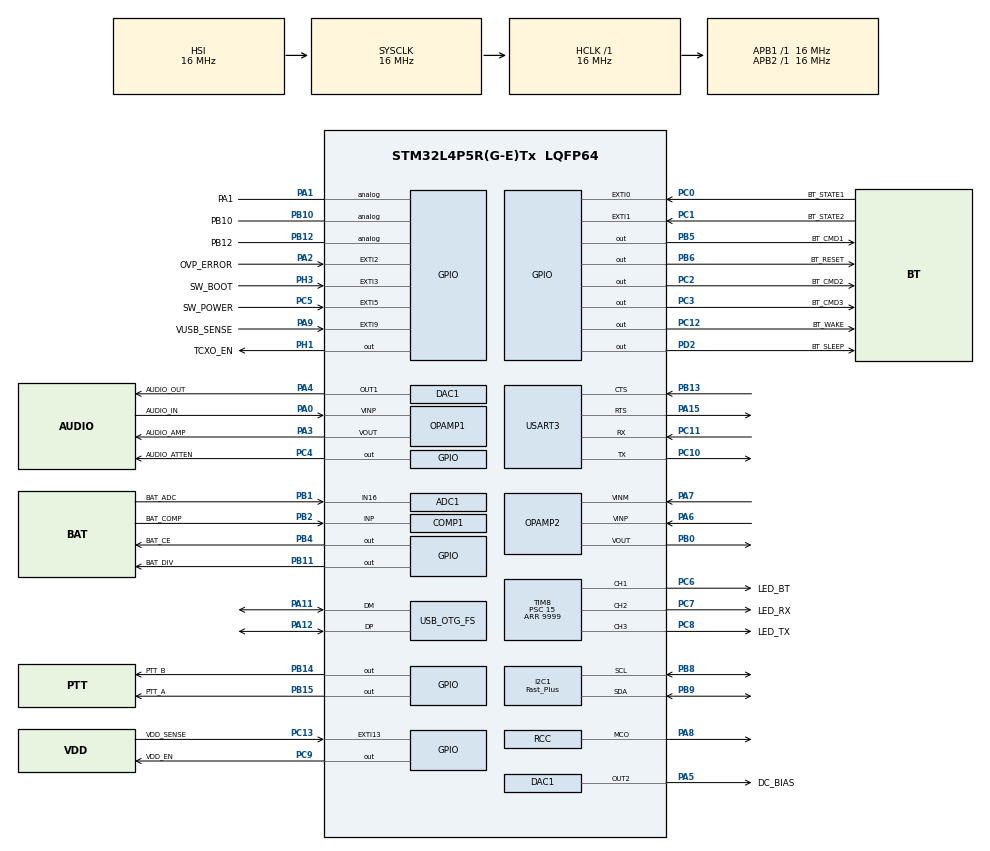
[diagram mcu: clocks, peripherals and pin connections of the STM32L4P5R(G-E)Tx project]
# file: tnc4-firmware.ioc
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ADC1.Channel-0\#ChannelRegularConversion=ADC_CHANNEL_16
ADC1.DMAContinuousRequests=DISABLE
ADC1.ExternalTrigConv=ADC_SOFTWARE_START
ADC1.NbrOfConversionFlag=1
ADC1.OffsetNumber-0\#ChannelRegularConversion=ADC_OFFSET_NONE
ADC1.OversamplingMode=ENABLE
ADC1.Rank-0\#ChannelRegularConversion=1
ADC1.Ratio=ADC_OVERSAMPLING_RATIO_16
ADC1.RightBitShift=ADC_RIGHTBITSHIFT_2
ADC1.SamplingTime-0\#ChannelRegularConversion=ADC_SAMPLETIME_640CYCLES_5
ADC1.master=1
ADC2.Channel-4\#ChannelRegularConversion=ADC_CHANNEL_8
ADC2.ClockPrescaler=ADC_CLOCK_ASYNC_DIV1
ADC2.DMAContinuousRequests=ENABLE
ADC2.ExternalTrigConv=ADC_EXTERNALTRIG_T6_TRGO
ADC2.NbrOfConversionFlag=1
ADC2.OffsetNumber-4\#ChannelRegularConversion=ADC_OFFSET_NONE
ADC2.OversamplingMode=ENABLE
ADC2.Rank-4\#ChannelRegularConversion=1
ADC2.Ratio=ADC_OVERSAMPLING_RATIO_16
ADC2.RightBitShift=ADC_RIGHTBITSHIFT_2
ADC2.SamplingTime-4\#ChannelRegularConversion=ADC_SAMPLETIME_24CYCLES_5
COMP1.Hysteresis=COMP_HYSTERESIS_LOW
COMP1.Mode=COMP_POWERMODE_ULTRALOWPOWER
COMP1.TriggerMode=COMP_TRIGGERMODE_IT_FALLING
CRC.CRCLength=CRC_POLYLENGTH_16B
CRC.DefaultInitValueUse=DEFAULT_INIT_VALUE_DISABLE
CRC.DefaultPolynomialUse=DEFAULT_POLYNOMIAL_DISABLE
CRC.GeneratingPolynomial=X12+X5+X0
CRC.InitValue=0xFFFF
CRC.InputDataInversionMode=CRC_INPUTDATA_INVERSION_BYTE
DAC1.DAC_Channel-DAC_OUT2=DAC_CHANNEL_2
DAC1.DAC_SampleAndHold-DAC_OUT2=DAC_SAMPLEANDHOLD_DISABLE
DAC1.DAC_Trigger-DAC_OUT1=DAC_TRIGGER_T7_TRGO
Dma.ADC2.5.Direction=DMA_PERIPH_TO_MEMORY
Dma.ADC2.5.EventEnable=ENABLE
Dma.ADC2.5.Instance=DMA1_Channel3
Dma.ADC2.5.MemDataAlignment=DMA_MDATAALIGN_HALFWORD
Dma.ADC2.5.MemInc=DMA_MINC_ENABLE
Dma.ADC2.5.Mode=DMA_CIRCULAR
Dma.ADC2.5.PeriphDataAlignment=DMA_PDATAALIGN_HALFWORD
Dma.ADC2.5.PeriphInc=DMA_PINC_DISABLE
Dma.ADC2.5.Polarity=HAL_DMAMUX_REQ_GEN_RISING
Dma.ADC2.5.Priority=DMA_PRIORITY_LOW
Dma.ADC2.5.RequestNumber=1
Dma.ADC2.5.SignalID=NONE
Dma.ADC2.5.SyncEnable=DISABLE
Dma.ADC2.5.SyncPolarity=HAL_DMAMUX_SYNC_NO_EVENT
Dma.ADC2.5.SyncRequestNumber=1
Dma.ADC2.5.SyncSignalID=NONE
Dma.DAC1_CH1.2.Direction=DMA_MEMORY_TO_PERIPH
Dma.DAC1_CH1.2.EventEnable=DISABLE
Dma.DAC1_CH1.2.Instance=DMA1_Channel4
Dma.DAC1_CH1.2.MemDataAlignment=DMA_MDATAALIGN_HALFWORD
Dma.DAC1_CH1.2.MemInc=DMA_MINC_ENABLE
Dma.DAC1_CH1.2.Mode=DMA_CIRCULAR
Dma.DAC1_CH1.2.PeriphDataAlignment=DMA_PDATAALIGN_HALFWORD
Dma.DAC1_CH1.2.PeriphInc=DMA_PINC_DISABLE
Dma.DAC1_CH1.2.Polarity=HAL_DMAMUX_REQ_GEN_RISING
Dma.DAC1_CH1.2.Priority=DMA_PRIORITY_VERY_HIGH
Dma.DAC1_CH1.2.RequestNumber=1
Dma.DAC1_CH1.2.SignalID=NONE
Dma.DAC1_CH1.2.SyncEnable=DISABLE
Dma.DAC1_CH1.2.SyncPolarity=HAL_DMAMUX_SYNC_NO_EVENT
Dma.DAC1_CH1.2.SyncRequestNumber=1
Dma.DAC1_CH1.2.SyncSignalID=NONE
Dma.I2C1_RX.3.Direction=DMA_PERIPH_TO_MEMORY
Dma.I2C1_RX.3.EventEnable=DISABLE
Dma.I2C1_RX.3.Instance=DMA1_Channel5
Dma.I2C1_RX.3.MemDataAlignment=DMA_MDATAALIGN_BYTE
Dma.I2C1_RX.3.MemInc=DMA_MINC_ENABLE
Dma.I2C1_RX.3.Mode=DMA_NORMAL
Dma.I2C1_RX.3.PeriphDataAlignment=DMA_PDATAALIGN_BYTE
Dma.I2C1_RX.3.PeriphInc=DMA_PINC_DISABLE
Dma.I2C1_RX.3.Polarity=HAL_DMAMUX_REQ_GEN_RISING
Dma.I2C1_RX.3.Priority=DMA_PRIORITY_LOW
Dma.I2C1_RX.3.RequestNumber=1
Dma.I2C1_RX.3.SignalID=NONE
Dma.I2C1_RX.3.SyncEnable=DISABLE
Dma.I2C1_RX.3.SyncPolarity=HAL_DMAMUX_SYNC_NO_EVENT
Dma.I2C1_RX.3.SyncRequestNumber=1
Dma.I2C1_RX.3.SyncSignalID=NONE
Dma.I2C1_TX.4.Direction=DMA_MEMORY_TO_PERIPH
Dma.I2C1_TX.4.EventEnable=DISABLE
Dma.I2C1_TX.4.Instance=DMA1_Channel6
Dma.I2C1_TX.4.MemDataAlignment=DMA_MDATAALIGN_BYTE
Dma.I2C1_TX.4.MemInc=DMA_MINC_ENABLE
Dma.I2C1_TX.4.Mode=DMA_NORMAL
Dma.I2C1_TX.4.PeriphDataAlignment=DMA_PDATAALIGN_BYTE
Dma.I2C1_TX.4.PeriphInc=DMA_PINC_DISABLE
Dma.I2C1_TX.4.Polarity=HAL_DMAMUX_REQ_GEN_RISING
Dma.I2C1_TX.4.Priority=DMA_PRIORITY_LOW
Dma.I2C1_TX.4.RequestNumber=1
Dma.I2C1_TX.4.SignalID=NONE
Dma.I2C1_TX.4.SyncEnable=DISABLE
Dma.I2C1_TX.4.SyncPolarity=HAL_DMAMUX_SYNC_NO_EVENT
Dma.I2C1_TX.4.SyncRequestNumber=1
Dma.I2C1_TX.4.SyncSignalID=NONE
Dma.Request0=USART3_RX
Dma.Request1=USART3_TX
Dma.Request2=DAC1_CH1
Dma.Request3=I2C1_RX
Dma.Request4=I2C1_TX
Dma.Request5=ADC2
Dma.USART3_RX.0.Direction=DMA_PERIPH_TO_MEMORY
Dma.USART3_RX.0.EventEnable=DISABLE
Dma.USART3_RX.0.Instance=DMA1_Channel1
Dma.USART3_RX.0.MemDataAlignment=DMA_MDATAALIGN_BYTE
Dma.USART3_RX.0.MemInc=DMA_MINC_ENABLE
Dma.USART3_RX.0.Mode=DMA_CIRCULAR
Dma.USART3_RX.0.PeriphDataAlignment=DMA_PDATAALIGN_BYTE
Dma.USART3_RX.0.PeriphInc=DMA_PINC_DISABLE
Dma.USART3_RX.0.Polarity=HAL_DMAMUX_REQ_GEN_RISING
Dma.USART3_RX.0.Priority=DMA_PRIORITY_MEDIUM
Dma.USART3_RX.0.RequestNumber=1
Dma.USART3_RX.0.SignalID=NONE
Dma.USART3_RX.0.SyncEnable=DISABLE
Dma.USART3_RX.0.SyncPolarity=HAL_DMAMUX_SYNC_NO_EVENT
Dma.USART3_RX.0.SyncRequestNumber=1
Dma.USART3_RX.0.SyncSignalID=NONE
Dma.USART3_TX.1.Direction=DMA_MEMORY_TO_PERIPH
Dma.USART3_TX.1.EventEnable=DISABLE
Dma.USART3_TX.1.Instance=DMA1_Channel2
Dma.USART3_TX.1.MemDataAlignment=DMA_MDATAALIGN_BYTE
Dma.USART3_TX.1.MemInc=DMA_MINC_ENABLE
Dma.USART3_TX.1.Mode=DMA_NORMAL
Dma.USART3_TX.1.PeriphDataAlignment=DMA_PDATAALIGN_BYTE
Dma.USART3_TX.1.PeriphInc=DMA_PINC_DISABLE
Dma.USART3_TX.1.Polarity=HAL_DMAMUX_REQ_GEN_RISING
Dma.USART3_TX.1.Priority=DMA_PRIORITY_MEDIUM
Dma.USART3_TX.1.RequestNumber=1
Dma.USART3_TX.1.SignalID=NONE
Dma.USART3_TX.1.SyncEnable=DISABLE
Dma.USART3_TX.1.SyncPolarity=HAL_DMAMUX_SYNC_NO_EVENT
Dma.USART3_TX.1.SyncRequestNumber=1
Dma.USART3_TX.1.SyncSignalID=NONE
FREERTOS.HEAP_NUMBER=3
FREERTOS.Queues01=ioEventQueue,16,uint32_t,0,Static,ioEventQueueBuffer,ioEventQueueControlBlock;audioInputQueue,8,void*,0,Static,audioInputQueueBuffer,audioInputQueueControlBlock;hdlcInputQueue,3,uint32_t,0,Static,hdlcInputQueueBuffer,hdlcInputQueueControlBlock;hdlcOutputQueue,8,uint32_t,0,Static,hdlcOutputQueueBuffer,hdlcOutputQueueControlBlock;dacOutputQueue,128,uint8_t,0,Static,dacOutputQueueBuffer,dacOutputQueueControlBlock;adcInputQueue,3,void*,0,Static,adcInputQueueBuffer,adcInputQueueControlBlock;m17EncoderInputQueue,3,void*,0,Static,m17EncoderInputQueueBuffer,m17EncoderInputQueueControlBlock
FREERTOS.Tasks01=ioEventTask,-2,512,startIOEventTask,As weak,NULL,Static,ioEventTaskBuffer,ioEventTaskControlBlock;audioInputTask,1,512,startAudioInputTask,As external,NULL,Static,audioInputTaskBuffer,audioInputTaskControlBlock;modulatorTask,1,384,startModulatorTask,As external,NULL,Static,modulatorTaskBuffer,modulatorTaskControlBlock
FREERTOS.Timers01=usbShutdownTimer,usbShutdownTimerCallback,osTimerOnce,As external,NULL,Static,usbShutdownTimerControlBlock;powerOffTimer,powerOffTimerCallback,osTimerOnce,As external,NULL,Static,powerOffTimerControlBlock;batteryCheckTimer,batteryCheckCallback,osTimerPeriodic,As external,NULL,Static,batteryCheckTimerControlBlock
FREERTOS.configCHECK_FOR_STACK_OVERFLOW=1
FREERTOS.configENABLE_BACKWARD_COMPATIBILITY=1
FREERTOS.configENABLE_FPU=1
FREERTOS.configQUEUE_REGISTRY_SIZE=16
FREERTOS.configUSE_APPLICATION_TASK_TAG=0
FREERTOS.configUSE_MALLOC_FAILED_HOOK=1
FREERTOS.configUSE_NEWLIB_REENTRANT=1
FREERTOS.configUSE_TICKLESS_IDLE=2
FREERTOS.configUSE_TIMERS=1
I2C1.I2C_Speed_Mode=I2C_Fast_Plus
I2C1.Timing=0x00000107
IWDG.Prescaler=IWDG_PRESCALER_64
Mcu.Family=STM32L4
Mcu.Name=STM32L4P5R(G-E)Tx
Mcu.Package=LQFP64
Mcu.UserConstants=EEPROM_PAGE_SIZE,32;EEPROM_CAPACITY,4096;EEPROM_WRITE_TIME,10;EEPROM_ADDRESS,0xA0
NVIC.ADC1_2_IRQn=true\:5\:0\:false\:false\:true\:true\:true\:true\:true
NVIC.COMP_IRQn=true\:5\:0\:false\:false\:true\:true\:false\:true\:true
NVIC.DMA1_Channel1_IRQn=true\:5\:0\:false\:false\:true\:true\:false\:true\:true
NVIC.DMA1_Channel2_IRQn=true\:5\:0\:false\:false\:true\:true\:false\:true\:true
NVIC.DMA1_Channel3_IRQn=true\:5\:0\:false\:false\:true\:true\:false\:true\:true
NVIC.DMA1_Channel4_IRQn=true\:5\:0\:false\:false\:true\:true\:false\:true\:true
NVIC.DMA1_Channel5_IRQn=true\:5\:0\:false\:false\:true\:true\:false\:true\:true
NVIC.DMA1_Channel6_IRQn=true\:5\:0\:false\:false\:true\:true\:false\:true\:true
NVIC.DMAMUX1_OVR_IRQn=true\:5\:0\:false\:false\:true\:false\:false\:true\:true
NVIC.OTG_FS_IRQn=true\:5\:0\:false\:false\:true\:true\:false\:true\:true
NVIC.PriorityGroup=NVIC_PRIORITYGROUP_4
NVIC.TIM1_BRK_TIM15_IRQn=true\:15\:0\:false\:false\:true\:false\:false\:true\:true
NVIC.TIM8_UP_IRQn=true\:5\:0\:false\:false\:true\:true\:true\:true\:true
NVIC.TimeBase=TIM1_BRK_TIM15_IRQn
NVIC.TimeBaseIP=TIM15
NVIC.USART3_IRQn=true\:5\:0\:false\:false\:true\:true\:true\:true\:true
OPAMP1.PowerSupplyRange=OPAMP_POWERSUPPLY_HIGH
OPAMP2.PowerSupplyRange=OPAMP_POWERSUPPLY_HIGH
PA0.GPIO_Label=AUDIO_IN
PA0.Signal=SharedAnalog_PA0
PA1.GPIO_Label=PA1
PA1.Signal=GPIO_Analog
PA11.Mode=Device_Only
PA11.Signal=USB_OTG_FS_DM
PA12.Mode=Device_Only
PA12.Signal=USB_OTG_FS_DP
PA13\ (JTMS/SWDIO).Mode=Trace_Asynchronous_SW
PA13\ (JTMS/SWDIO).Signal=SYS_JTMS-SWDIO
PA14\ (JTCK/SWCLK).Mode=Trace_Asynchronous_SW
PA14\ (JTCK/SWCLK).Signal=SYS_JTCK-SWCLK
PA15\ (JTDI).Mode=CTS_RTS
PA15\ (JTDI).Signal=USART3_RTS
PA2.GPIO_Label=OVP_ERROR
PA2.GPIO_ModeDefaultEXTI=GPIO_MODE_IT_RISING_FALLING
PA2.Signal=SharedStack_PA2
PA2.Stacked=true
PA3.GPIO_Label=AUDIO_AMP
PA3.Signal=SharedAnalog_PA3
PA4.GPIO_Label=AUDIO_OUT
PA4.Signal=COMP_DAC11_group
PA5.GPIO_Label=DC_BIAS
PA5.Signal=COMP_DAC12_group
PA6.Mode=Standalone
PA6.Signal=OPAMP2_VINP
PA7.Mode=Standalone
PA7.Signal=OPAMP2_VINM
PA8.Mode=Clock-out
PA8.Signal=RCC_MCO
PA9.GPIO_Label=VUSB_SENSE
PA9.GPIO_ModeDefaultEXTI=GPIO_MODE_IT_RISING_FALLING
PA9.Signal=GPXTI9
PB0.Mode=Standalone
PB0.Signal=OPAMP2_VOUT
PB1.GPIO_Label=BAT_ADC
PB1.Signal=ADCx_IN16
PB10.GPIO_Label=PB10
PB10.Signal=GPIO_Analog
PB11.GPIO_Label=BAT_DIV
PB11.GPIO_ModeDefaultOutputPP=GPIO_MODE_OUTPUT_OD
PB11.PinState=GPIO_PIN_SET
PB11.Signal=GPIO_Output
PB12.GPIO_Label=PB12
PB12.Signal=GPIO_Analog
PB13.Mode=CTS_RTS
PB13.Signal=USART3_CTS
PB14.GPIO_Label=PTT_B
PB14.Signal=GPIO_Output
PB15.GPIO_Label=PTT_A
PB15.Signal=GPIO_Output
PB2.GPIO_Label=BAT_COMP
PB2.Mode=INP
PB2.Signal=COMP1_INP
PB3\ (JTDO/TRACESWO).Mode=Trace_Asynchronous_SW
PB3\ (JTDO/TRACESWO).Signal=SYS_JTDO-SWO
PB4\ (NJTRST).GPIO_Label=BAT_CE
PB4\ (NJTRST).GPIO_ModeDefaultOutputPP=GPIO_MODE_OUTPUT_OD
PB4\ (NJTRST).PinState=GPIO_PIN_SET
PB4\ (NJTRST).Signal=GPIO_Output
PB5.GPIO_Label=BT_CMD1
PB5.GPIO_ModeDefaultOutputPP=GPIO_MODE_OUTPUT_OD
PB5.PinState=GPIO_PIN_SET
PB5.Signal=GPIO_Output
PB6.GPIO_Label=BT_RESET
PB6.GPIO_ModeDefaultOutputPP=GPIO_MODE_OUTPUT_OD
PB6.PinState=GPIO_PIN_SET
PB6.Signal=GPIO_Output
PB7.Mode=Mode_PVD_Ext
PB7.Signal=SYS_PVD_IN
PB8.GPIO_Pu=GPIO_PULLUP
PB8.Mode=I2C
PB8.Signal=I2C1_SCL
PB9.GPIO_Pu=GPIO_PULLUP
PB9.Mode=I2C
PB9.Signal=I2C1_SDA
PC0.GPIO_Label=BT_STATE1
PC0.GPIO_ModeDefaultEXTI=GPIO_MODE_IT_RISING_FALLING
PC0.Signal=GPXTI0
PC1.GPIO_Label=BT_STATE2
PC1.GPIO_ModeDefaultEXTI=GPIO_MODE_IT_RISING_FALLING
PC1.Signal=GPXTI1
PC10.Mode=Asynchronous
PC10.Signal=USART3_TX
PC11.Mode=Asynchronous
PC11.Signal=USART3_RX
PC12.GPIO_Label=BT_WAKE
PC12.GPIO_ModeDefaultOutputPP=GPIO_MODE_OUTPUT_OD
PC12.PinState=GPIO_PIN_RESET
PC12.Signal=GPIO_Output
PC13.GPIO_Label=VDD_SENSE
PC13.GPIO_ModeDefaultEXTI=GPIO_MODE_IT_RISING_FALLING
PC13.Signal=SharedStack_PC13
PC13.Stacked=true
PC14-OSC32_IN\ (PC14).Mode=LSE-External-Oscillator
PC14-OSC32_IN\ (PC14).Signal=RCC_OSC32_IN
PC15-OSC32_OUT\ (PC15).Mode=LSE-External-Oscillator
PC15-OSC32_OUT\ (PC15).Signal=RCC_OSC32_OUT
PC2.GPIO_Label=BT_CMD2
PC2.GPIO_ModeDefaultOutputPP=GPIO_MODE_OUTPUT_OD
PC2.PinState=GPIO_PIN_SET
PC2.Signal=GPIO_Output
PC3.GPIO_Label=BT_CMD3
PC3.GPIO_ModeDefaultOutputPP=GPIO_MODE_OUTPUT_OD
PC3.PinState=GPIO_PIN_SET
PC3.Signal=GPIO_Output
PC4.GPIO_Label=AUDIO_ATTEN
PC4.GPIO_ModeDefaultOutputPP=GPIO_MODE_OUTPUT_OD
PC4.PinState=GPIO_PIN_SET
PC4.Signal=GPIO_Output
PC5.GPIO_Label=SW_POWER
PC5.GPIO_ModeDefaultEXTI=GPIO_MODE_IT_RISING_FALLING
PC5.Signal=SharedStack_PC5
PC5.Stacked=true
PC6.GPIO_Label=LED_BT
PC6.GPIO_ModeDefaultPP=GPIO_MODE_AF_OD
PC6.Signal=S_TIM8_CH1
PC7.GPIO_Label=LED_RX
PC7.GPIO_ModeDefaultPP=GPIO_MODE_AF_OD
PC7.Signal=S_TIM8_CH2
PC8.GPIO_Label=LED_TX
PC8.GPIO_ModeDefaultPP=GPIO_MODE_AF_OD
PC8.Signal=S_TIM8_CH3
PC9.GPIO_Label=VDD_EN
PC9.PinState=GPIO_PIN_RESET
PC9.Signal=GPIO_Output
PD2.GPIO_Label=BT_SLEEP
PD2.GPIO_ModeDefaultOutputPP=GPIO_MODE_OUTPUT_PP
PD2.PinState=GPIO_PIN_RESET
PD2.Signal=GPIO_Output
PH0-OSC_IN\ (PH0).GPIO_Label=TCXO_IN
PH0-OSC_IN\ (PH0).Mode=HSE-External-Clock-Source
PH0-OSC_IN\ (PH0).Signal=RCC_OSC_IN
PH1-OSC_OUT\ (PH1).GPIO_Label=TCXO_EN
PH1-OSC_OUT\ (PH1).GPIO_ModeDefaultOutputPP=GPIO_MODE_OUTPUT_PP
PH1-OSC_OUT\ (PH1).GPIO_PuPd=GPIO_NOPULL
PH1-OSC_OUT\ (PH1).GPIO_Speed=GPIO_SPEED_FREQ_LOW
PH1-OSC_OUT\ (PH1).PinState=GPIO_PIN_RESET
PH1-OSC_OUT\ (PH1).Signal=GPIO_Output
PH3-BOOT0.GPIO_Label=SW_BOOT
PH3-BOOT0.Signal=GPXTI3
ProjectManager.HeapSize=0x200
ProjectManager.StackSize=0x400
ProjectManager.TargetToolchain=CMake
RCC.ADCCLockSelection=RCC_ADCCLKSOURCE_SYSCLK
RCC.ADCFreq_Value=16000000
RCC.AHBFreq_Value=16000000
RCC.APB1Freq_Value=16000000
RCC.APB1TimFreq_Value=16000000
RCC.APB2Freq_Value=16000000
RCC.APB2TimFreq_Value=16000000
RCC.CK48CLockSelection=RCC_USBCLKSOURCE_HSI48
RCC.CortexFreq_Value=16000000
RCC.HCLKFreq_Value=16000000
RCC.HSE_VALUE=24000000
RCC.HSI48_VALUE=48000000
RCC.HSI_VALUE=16000000
RCC.I2C1CLockSelection=RCC_I2C1CLKSOURCE_HSI
RCC.I2C3CLockSelection=RCC_I2C3CLKSOURCE_HSI
RCC.LSCOSource1=RCC_LSCOSOURCE_LSE
RCC.MSIClockRange=RCC_MSIRANGE_8
RCC.MSI_VALUE=16000000
RCC.PLLM1=3
RCC.PLLM2=3
RCC.PLLN=12
RCC.PLLSAI1N=24
RCC.PLLSAI1Q=RCC_PLLQ_DIV4
RCC.PLLSAI1R=RCC_PLLR_DIV4
RCC.PLLSourceVirtual=RCC_PLLSOURCE_HSI
RCC.RCC_MCODiv=RCC_MCODIV_8
RCC.RTCClockSelection=RCC_RTCCLKSOURCE_LSE
RCC.SYSCLKFreq_VALUE=16000000
RCC.SYSCLKSource=RCC_SYSCLKSOURCE_HSI
RCC.USART3CLockSelection=RCC_USART3CLKSOURCE_HSI
RCC.USBFreq_Value=48000000
RCC.VCOOutputFreq_Value=64000000
RNG.ClockErrorDetection=RNG_CED_ENABLE
SH.ADCx_IN16.0=ADC2_IN16
SH.ADCx_IN16.1=ADC1_IN16,IN16-Single-Ended
SH.COMP_DAC11_group.0=DAC1_OUT1,DAC_OUT1
SH.COMP_DAC12_group.0=DAC1_OUT2,DAC_OUT2
SH.S_TIM8_CH1.0=TIM8_CH1,PWM Generation1 CH1
SH.S_TIM8_CH2.0=TIM8_CH2,PWM Generation2 CH2
SH.S_TIM8_CH3.0=TIM8_CH3,PWM Generation3 CH3
SH.SharedAnalog_PA0.0=ADC1_IN5
SH.SharedAnalog_PA0.1=ADC2_IN5
SH.SharedAnalog_PA0.2=OPAMP1_VINP,PGA Not Connected
SH.SharedAnalog_PA3.0=ADC1_IN8
SH.SharedAnalog_PA3.1=OPAMP1_VOUT,PGA Not Connected
SH.SharedAnalog_PA3.2=ADC2_IN8,IN8-Single-Ended
SH.SharedStack_PA2.0=SYS_WKUP4
SH.SharedStack_PA2.1=GPIO_EXTI2
SH.SharedStack_PC13.0=SYS_WKUP2
SH.SharedStack_PC13.1=GPIO_EXTI13
SH.SharedStack_PC5.0=SYS_WKUP5
SH.SharedStack_PC5.1=GPIO_EXTI5
STMicroelectronics.X-CUBE-ALGOBUILD.1.2.0.LibraryCcDSPOoLibraryJjDSPOoLibrary=true
TIM4.Period=15624
TIM4.Prescaler=32
TIM4.TIM_MasterOutputTrigger=TIM_TRGO_UPDATE
TIM6.Period=2499
TIM6.TIM_MasterOutputTrigger=TIM_TRGO_UPDATE
TIM7.Period=2499
TIM7.TIM_MasterOutputTrigger=TIM_TRGO_UPDATE
TIM8.Channel-PWM\ Generation1\ CH1=TIM_CHANNEL_1
TIM8.Channel-PWM\ Generation2\ CH2=TIM_CHANNEL_2
TIM8.Channel-PWM\ Generation3\ CH3=TIM_CHANNEL_3
TIM8.OC1Preload_PWM=ENABLE
TIM8.OCIdleState_1=TIM_OCIDLESTATE_SET
TIM8.OCIdleState_2=TIM_OCIDLESTATE_SET
TIM8.OCIdleState_3=TIM_OCIDLESTATE_SET
TIM8.OCPolarity_1=TIM_OCPOLARITY_LOW
TIM8.OCPolarity_2=TIM_OCPOLARITY_LOW
TIM8.OCPolarity_3=TIM_OCPOLARITY_LOW
TIM8.Period=9999
TIM8.Prescaler=15
USART3.FIFOMode=FIFOMODE_ENABLE
USART3.VirtualMode-Asynchronous=VM_ASYNC
USB_DEVICE.CLASS_NAME_FS=CDC
USB_DEVICE.MANUFACTURER_STRING=Mobilinkd LLC
USB_DEVICE.PRODUCT_STRING_CDC_FS=Mobilinkd TNC4
USB_DEVICE.USBD_LPM_ENABLED=0
USB_DEVICE.USBD_SELF_POWERED=1
USB_DEVICE.VirtualMode=Cdc
USB_DEVICE.VirtualModeFS=Cdc_FS
USB_OTG_FS.VirtualMode=Device_Only
VP_ADC1_Vref_Input.Mode=IN-Vrefint
VP_COMP1_VS_VREFINT34.Mode=VREFINT_34
VP_CRC_VS_CRC.Mode=CRC_Activate
VP_FREERTOS_VS_CMSIS_V1.Mode=CMSIS_V1
VP_IWDG_VS_IWDG.Mode=IWDG_Activate
VP_RNG_VS_RNG.Mode=RNG_Activate
VP_RTC_VS_RTC_Activate.Mode=RTC_Enabled
VP_RTC_VS_RTC_Calendar.Mode=RTC_Calendar
VP_STMicroelectronics.X-CUBE-ALGOBUILD_VS_DSPOoLibraryJjLibrary_1.2.0_1.2.0.Mode=DSPOoLibraryJjLibrary
VP_SYS_VS_tim15.Mode=TIM15
VP_TIM4_VS_ClockSourceINT.Mode=Internal
VP_TIM6_VS_ClockSourceINT.Mode=Enable_Timer
VP_TIM7_VS_ClockSourceINT.Mode=Enable_Timer
VP_TIM8_VS_ClockSourceINT.Mode=Internal
VP_USB_DEVICE_VS_USB_DEVICE_CDC_FS.Mode=CDC_FS
board=custom

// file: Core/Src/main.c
/* USER CODE BEGIN Header */
/**
  ******************************************************************************
  * @file           : main.c
  * @brief          : Main program body
  ******************************************************************************
  * @attention
  *
  * <h2><center>&copy; Copyright (c) 2021 STMicroelectronics.
  * All rights reserved.</center></h2>
  *
  * This software component is licensed by ST under Ultimate Liberty license
  * SLA0044, the "License"; You may not use this file except in compliance with
  * the License. You may obtain a copy of the License at:
  *                             www.st.com/SLA0044
  *
  ******************************************************************************
  */
/* USER CODE END Header */
#include "main.h"
#include "cmsis_os.h"

/* USER CODE BEGIN Includes */
#include "stm32l4xx_it.h"
#include "usbd_core.h"
#include "IOEventTask.h"
#include "PortInterface.h"
#include "LEDIndicator.h"
#include "bm78.h"
#include "KissHardware.h"
#include "Log.h"
#include "Digipeater.h"
#include "power.h"

/* USER CODE END Includes */

ADC_HandleTypeDef hadc1;
ADC_HandleTypeDef hadc2;
DMA_HandleTypeDef hdma_adc2;

COMP_HandleTypeDef hcomp1;

CRC_HandleTypeDef hcrc;

DAC_HandleTypeDef hdac1;
DMA_HandleTypeDef hdma_dac1_ch1;

I2C_HandleTypeDef hi2c1;
DMA_HandleTypeDef hdma_i2c1_rx;
DMA_HandleTypeDef hdma_i2c1_tx;

IWDG_HandleTypeDef hiwdg;

OPAMP_HandleTypeDef hopamp1;
OPAMP_HandleTypeDef hopamp2;

RNG_HandleTypeDef hrng;

RTC_HandleTypeDef hrtc;

TIM_HandleTypeDef htim4;
TIM_HandleTypeDef htim6;
TIM_HandleTypeDef htim7;
TIM_HandleTypeDef htim8;

UART_HandleTypeDef huart3;
DMA_HandleTypeDef hdma_usart3_rx;
DMA_HandleTypeDef hdma_usart3_tx;

osThreadId ioEventTaskHandle;
uint32_t ioEventTaskBuffer[ 512 ];
osStaticThreadDef_t ioEventTaskControlBlock;
osThreadId audioInputTaskHandle;
uint32_t audioInputTaskBuffer[ 512 ];
osStaticThreadDef_t audioInputTaskControlBlock;
osThreadId modulatorTaskHandle;
uint32_t modulatorTaskBuffer[ 384 ];
osStaticThreadDef_t modulatorTaskControlBlock;
osThreadId digipeaterTaskHandle;
uint32_t digipeaterTaskBuffer[ 256 ];
osStaticThreadDef_t digipeaterTaskControlBlock;
osMessageQId ioEventQueueHandle;
uint8_t ioEventQueueBuffer[ 16 * sizeof( uint32_t ) ];
osStaticMessageQDef_t ioEventQueueControlBlock;
osMessageQId audioInputQueueHandle;
uint8_t audioInputQueueBuffer[ 8 * sizeof( void* ) ];
osStaticMessageQDef_t audioInputQueueControlBlock;
osMessageQId hdlcInputQueueHandle;
uint8_t hdlcInputQueueBuffer[ 3 * sizeof( uint32_t ) ];
osStaticMessageQDef_t hdlcInputQueueControlBlock;
osMessageQId hdlcOutputQueueHandle;
uint8_t hdlcOutputQueueBuffer[ 8 * sizeof( uint32_t ) ];
osStaticMessageQDef_t hdlcOutputQueueControlBlock;
osMessageQId dacOutputQueueHandle;
uint8_t dacOutputQueueBuffer[ 128 * sizeof( uint8_t ) ];
osStaticMessageQDef_t dacOutputQueueControlBlock;
osMessageQId adcInputQueueHandle;
uint8_t adcInputQueueBuffer[ 3 * sizeof( void* ) ];
osStaticMessageQDef_t adcInputQueueControlBlock;
osMessageQId m17EncoderInputQueueHandle;
uint8_t m17EncoderInputQueueBuffer[ 3 * sizeof( void* ) ];
osStaticMessageQDef_t m17EncoderInputQueueControlBlock;
osMessageQId digipeaterQueueHandle;
uint8_t digipeaterQueueBuffer[ 8 * sizeof( uint32_t ) ];
osStaticMessageQDef_t digipeaterQueueControlBlock;
osTimerId usbShutdownTimerHandle;
osStaticTimerDef_t usbShutdownTimerControlBlock;
osTimerId powerOffTimerHandle;
osStaticTimerDef_t powerOffTimerControlBlock;
osTimerId batteryCheckTimerHandle;
osStaticTimerDef_t batteryCheckTimerControlBlock;
/* USER CODE BEGIN PV */

int lost_power = 0;
int reset_requested = 0;
char serial_number_64[24] = {0};

/*
 * The TNC will restart for a number of reasons:
 *
 * - Initial power on due to loss of power (backup domain not retained).
 * - Restart due to shutdown or restart from firmware update (backup domain
 *   retained).
 * - Restart due to watchdog timeout (backup domain retained).
 * - Restart to stop mode (SRAM, backup domain retained).
 * - Restart due to ErrorHandler() call (SRAM, backup domain retained).
 */

// Make sure it is not overwritten during resets (safedata).
uint8_t mac_address[6] __attribute__((section(".safedata")));
char error_message[80] __attribute__((section(".safedata")));

// USB power control -- need to renegotiate USB charging in STOP mode.
int go_back_to_sleep __attribute__((section(".safedata")));
int charging_enabled __attribute__((section(".safedata")));
int usb_wake_state __attribute__((section(".safedata")));
int bt_connected __attribute__((section(".safedata")));

int reset_button = 0;
extern void* testTonePtr;

uint16_t mobilinkd_model;
uint16_t mobilindk_date_code;
uint32_t mobilinkd_serial_number;

extern TIM_HandleTypeDef htim15;

/* USER CODE END PV */

void SystemClock_Config(void);
void startIOEventTask(void const * argument);
extern void startAudioInputTask(void const * argument);
extern void startModulatorTask(void const * argument);
extern void usbShutdownTimerCallback(void const * argument);
extern void powerOffTimerCallback(void const * argument);
extern void batteryCheckCallback(void const * argument);

/* USER CODE BEGIN PFP */
void enable_debug_gpio(void);
void init_rtc_date_time(void);
void init_rtc_alarm(void);

/* USER CODE END PFP */

/* USER CODE BEGIN 0 */

/*
 * Same algorithm as here: https://github.com/libopencm3/libopencm3/blob/master/lib/stm32/desig.c
 */
void encode_serial_number()
{
    uint8_t *uid = (uint8_t *)UID_BASE;

    uint8_t serial[6];
    serial[0] = uid[11];
    serial[1] = uid[10] + uid[2];
    serial[2] = uid[9];
    serial[3] = uid[8] + uid[0];
    serial[4] = uid[7];
    serial[5] = uid[6];

    snprintf(
        serial_number_64,
        sizeof(serial_number_64),
        "%02X%02X%02X%02X%02X%02X (%04lu)",
        serial[0], serial[1], serial[2],
        serial[3], serial[4], serial[5],
        mobilinkd_serial_number
    );
}

/* USER CODE END 0 */

int main(void)
{

  /* USER CODE BEGIN 1 */

    uint32_t wakeEvent = PWR->SR1 & 0x1F;

    // Capture cause of reset.
    ResetCause resetCause = RESET_CAUSE_UNKNOWN;
    if (RCC->CSR & RCC_CSR_SFTRSTF) {
        resetCause = RESET_CAUSE_SOFT;
    } else if (RCC->CSR & RCC_CSR_IWDGRSTF) {
        resetCause = RESET_CAUSE_IWDG;
    } else if (RCC->CSR & RCC_CSR_PINRSTF) {
        resetCause = RESET_CAUSE_HARD;
        reset_button = 1;
    } else if (RCC->CSR & RCC_CSR_BORRSTF) {
        resetCause = RESET_CAUSE_BOR;
    } else if (wakeEvent) {
        resetCause = RESET_CAUSE_WUF;
    } else if (__HAL_RTC_WAKEUPTIMER_GET_FLAG(&hrtc, RTC_FLAG_WUTF) != RESET) {
        resetCause = RESET_CAUSE_WUTF;
    }

    // Read serial, model, date from OTP record. Values are big-endian.
    mobilinkd_serial_number = __builtin_bswap32(*(uint32_t*) (0x1FFF7000));
    mobilinkd_model = __builtin_bswap16(*(uint16_t*) (0x1FFF7004));
    mobilindk_date_code = __builtin_bswap16(*(uint16_t*) (0x1FFF7006));

  /* USER CODE END 1 */

  /* MCU Configuration--------------------------------------------------------*/

  /* Reset of all peripherals, Initializes the Flash interface and the Systick. */
  HAL_Init();

  /* USER CODE BEGIN Init */
    __HAL_RCC_PLL_DISABLE(); // Work around HAL_RCC_OscConfig bug.
    __HAL_DBGMCU_FREEZE_IWDG();

    // Disable GPIO pull-up/down otherwise the shutdown pull-up/pull-down
    // remain active after restart.
    HAL_PWR_EnableBkUpAccess();
    HAL_PWREx_DisablePullUpPullDownConfig();
    HAL_PWREx_DisableGPIOPullDown(PWR_GPIO_C, PWR_GPIO_BIT_9);    // VDD_EN
    HAL_PWR_DisableBkUpAccess();

  /* USER CODE END Init */

  /* Configure the system clock */
  SystemClock_Config();

  /* USER CODE BEGIN SysInit */

    // SysClock starts at 16MHz and we want a 2MHz SWO.
    TPI->ACPR = 7;

    // Note that it is important that all GPIO interrupts are disabled until
    // the FreeRTOS kernel has started.  All GPIO interrupts  send messages
    // to the ioEventTask thread.  Attempts to use any message queues before
    // FreeRTOS has started will lead to problems.  Because of this, GPIO
    // interrupts are enabled only when the ioEventTask thread starts.

  /* USER CODE END SysInit */

  /* Initialize all configured peripherals */
  MX_GPIO_Init();
  MX_DMA_Init();
  MX_TIM8_Init();
  MX_RTC_Init();
  MX_TIM4_Init();
  /* USER CODE BEGIN 2 */

    GPIO_PinState power_switch_state = !!(SW_POWER_GPIO_Port->IDR & SW_POWER_Pin);

    // Log the cause of the reset.
    switch (resetCause) {
    case RESET_CAUSE_SOFT:
        INFO("software reset");
        break;
    case RESET_CAUSE_IWDG:
        INFO("watchdog reset");
        // Reset the BKUP_TNC_LOWPOWER_STATE register to ensure the TNC wakes
        // after a watchdog reset.
        HAL_PWR_EnableBkUpAccess();
        WRITE_REG(BKUP_TNC_LOWPOWER_STATE, 0x0);
        HAL_PWR_DisableBkUpAccess();
        break;
    case RESET_CAUSE_HARD:
        INFO("hardware reset");
        // Reset the BKUP_TNC_LOWPOWER_STATE register to ensure the TNC wakes
        // after a hardware reset.
        HAL_PWR_EnableBkUpAccess();
        WRITE_REG(BKUP_TNC_LOWPOWER_STATE, 0x0);
        HAL_PWR_DisableBkUpAccess();
        break;
    case RESET_CAUSE_BOR:
        INFO("brown-out reset");
        break;
    case RESET_CAUSE_WUF:
        INFO("wake-up event: %02lx", wakeEvent);
        break;
    case RESET_CAUSE_WUTF:
        INFO("wake-up timer");
        break;
    default:
        INFO("unknown reset, RCC->CSR=0x%08lx", RCC->CSR);
        INFO("unknown reset, RTC->SR=0x%08lx", RTC->SR);
        INFO("unknown reset, PWR->SR1=0x%08lx", PWR->SR1);
    }

    INFO("PWR->SCR=0x%08lx", PWR->SCR);
    INFO("PWR->CR1=0x%08lx", PWR->CR1);

    __HAL_RCC_CLEAR_RESET_FLAGS();

    uint32_t shutdown_reg = READ_REG(BKUP_TNC_LOWPOWER_STATE);

    // Reset the BKUP_TNC_LOWPOWER_STATE register.
    HAL_PWR_EnableBkUpAccess();
    WRITE_REG(BKUP_TNC_LOWPOWER_STATE, 0x0);
    HAL_PWR_DisableBkUpAccess();

    if (shutdown_reg & TNC_LOWPOWER_DFU) {
        // DFU leaves the system in a bad state. This starts clean.
        HAL_NVIC_SystemReset();
    }

    // TNC_LOWPOWER_RECONFIG is used to negotiate USB power when the device
    // is connected to USB while in a low-power state.
    go_back_to_sleep = !!(shutdown_reg & TNC_LOWPOWER_RECONFIG); // Need to return to sleep.

    // If shutdown because battery is low and there is no VUSB, shutdown again.
    if ((shutdown_reg & TNC_LOWPOWER_LOW_BAT)
            && !(VUSB_SENSE_GPIO_Port->IDR & VUSB_SENSE_Pin)) {
        HAL_PWR_EnableBkUpAccess();
        WRITE_REG(BKUP_TNC_LOWPOWER_STATE, TNC_LOWPOWER_LOW_BAT);
        HAL_PWR_DisableBkUpAccess();
        WARN("Battery too low to start");
        indicate_battery_low();
        HAL_Delay(3000);
        go_back_to_sleep = 1;
    }

    INFO("start");

    if (resetCause == RESET_CAUSE_SOFT && error_message[0] != 0) {
        error_message[79] = 0;
        WARN(error_message);
    }
    error_message[0] = 0;

    if (shutdown_reg == 0) {
        memset(mac_address, 0, 6);
        memset(error_message, 0, 80);
        charging_enabled = 0;
        usb_wake_state = 0;
    }

    // Needed to check battery level.
    enable_vdd();
    HAL_Delay(10);
    MX_ADC1_Init();
    if (HAL_ADCEx_Calibration_Start(&BATTERY_ADC_HANDLE, ADC_SINGLE_ENDED)
            != HAL_OK) {
        Error_Handler();
    }

#if 0
    // Currently only TNC_LOWPOWER_SHUTDOWN when VBAT is low.
    if (shutdown_reg & TNC_LOWPOWER_SHUTDOWN) {
        WakeType wake = SHUTDOWN;
        INFO("wake up");
        // OVP will glitch for 1ms when VUSB is enabled.
        if ((resetCause == RESET_CAUSE_WUF) && (wakeEvent & PWR_WAKEUP_PIN4)
                && !(OVP_ERROR_GPIO_Port->IDR & OVP_ERROR_Pin)) {    // OVP Error
            ERROR("over voltage");
            indicate_ovp_error();
            HAL_Delay(3000);    // Indicate OVP Error for at least 3 seconds.
            while (!(OVP_ERROR_GPIO_Port->IDR & OVP_ERROR_Pin)) {
                // Read battery level and shutdown if too low, otherwise sleep 5 minutes and repeat.
                if (HAL_GetTick() - start > 300000) {
                    if (is_battery_low()) {
                        WARN("low battery");
                        indicate_battery_low();
                        HAL_Delay(3030);
                        shutdown(TNC_LOWPOWER_VBAT | TNC_LOWPOWER_LOW_BAT);
                    }
                    start = HAL_GetTick();
                }
            }
            if ((shutdown_reg & TNC_LOWPOWER_VBAT)
                    && (VUSB_SENSE_GPIO_Port->IDR & VUSB_SENSE_Pin)) {
                wake = WAKE_UP;
            }
        } else if ((resetCause == RESET_CAUSE_WUF)
                && (wakeEvent & PWR_WAKEUP_PIN5)) {                    // SW_POWER
            INFO("power switch pressed");
            wake = SHUTDOWN;
            while ((SW_POWER_GPIO_Port->IDR & SW_POWER_Pin) != 0) {
                if (HAL_GetTick() - start > 3000) {
                    wake = WAKE_UP;
                    break;
                }
            }
            if (wake == SHUTDOWN) {
                INFO("power switch press too short");
            }
        } else if (resetCause == RESET_CAUSE_WUF
                && (wakeEvent & PWR_WAKEUP_PIN2)
                && (VUSB_SENSE_GPIO_Port->IDR & VUSB_SENSE_Pin)) {     // VDD_SENSE
            INFO("USB power available");
            // Power must be present for more than 2 seconds.
            uint32_t start = HAL_GetTick();
            while (VUSB_SENSE_GPIO_Port->IDR & VUSB_SENSE_Pin) {
                if (HAL_GetTick() - start > 2000) {
                    wake = WAKE_UP;
                    break;
                }
            }
            if (wake == WAKE_UP
                    && !(power_config_reg & POWER_CONFIG_WAKE_FROM_USB)) {
                wake = SHUTDOWN;
            }
        } else if ((shutdown_reg & TNC_LOWPOWER_VUSB)
                && !(VUSB_SENSE_GPIO_Port->IDR & VUSB_SENSE_Pin)) {
            // Wake from USB
            INFO("USB power lost");
            wake = SHUTDOWN;
        } else if (resetCause == RESET_CAUSE_WUTF) {
            INFO("RTC wake up");
            __HAL_RTC_WAKEUPTIMER_CLEAR_FLAG(&hrtc, RTC_FLAG_WUTF);
            wake = WAKE_UP;
        } else if (resetCause != RESET_CAUSE_UNKNOWN) {
            WARN("Spurious wake up event");
            wake = WAKE_UP;
        } else {
            WARN("Unknown wake up event");
            wake = WAKE_UP;
        }

        if (wake == SHUTDOWN) {
            shutdown(
                    VUSB_SENSE_GPIO_Port->IDR & VUSB_SENSE_Pin ?
                            TNC_LOWPOWER_VUSB : TNC_LOWPOWER_VBAT);
        }

        INFO("waking...");
    }
#endif

    // Don't start up at all if battery is low.
    if (!go_back_to_sleep && is_battery_low()) {
        WARN("low battery");
        indicate_battery_low();
        HAL_PWR_EnableBkUpAccess();
        WRITE_REG(BKUP_TNC_LOWPOWER_STATE, TNC_LOWPOWER_LOW_BAT);
        HAL_PWR_DisableBkUpAccess();
        HAL_Delay(3000);
        go_back_to_sleep = 1;
    }

    SCB->SHCSR |= 0x70000;    // Enable fault handlers;
    if (!go_back_to_sleep) {
        indicate_turning_on();    // LEDs on during boot.
        if (power_switch_state && reset_button) {
            reset_requested = 1;
        }
    }

    encode_serial_number();
    // ADC1 already initialized and calibrated.
    MX_ADC2_Init();
    MX_DAC1_Init();
    MX_OPAMP1_Init();
    MX_TIM6_Init();
    MX_TIM7_Init();
    MX_CRC_Init();
    MX_RNG_Init();
    MX_I2C1_Init();
    MX_IWDG_Init();

    if (!go_back_to_sleep) {
        MX_USART3_UART_Init(); // Initialize UART.
        HAL_GPIO_WritePin(BT_SLEEP_GPIO_Port, BT_SLEEP_Pin, GPIO_PIN_SET); // BT module on.
        HAL_GPIO_WritePin(BT_RESET_GPIO_Port, BT_RESET_Pin, GPIO_PIN_RESET); // BT module out of reset.
        HAL_Delay(1);
        HAL_GPIO_WritePin(BT_RESET_GPIO_Port, BT_RESET_Pin, GPIO_PIN_SET); // BT module out of reset.
        bm78_wait_until_ready();

        // Initialize the BM78 Bluetooth module. Note that a CPU speed of 2MHz
        // here will cause this to fail.
        if (!bm78_initialized() || reset_requested) {
            bm78_initialize();
        } else {
            bm78_initialize_mac_address();
        }

        HAL_IWDG_Refresh(&hiwdg);

        // Initialize the DC offset DAC and the PGA op amp.  Calibrate the ADC.
        if (HAL_DAC_SetValue(&hdac1, DAC_CHANNEL_2, DAC_ALIGN_12B_R, 1024)
                != HAL_OK)
            Error_Handler();
        if (HAL_DAC_Start(&hdac1, DAC_CHANNEL_2) != HAL_OK)
            Error_Handler();
        if (HAL_OPAMP_SelfCalibrate(&hopamp1) != HAL_OK)
            Error_Handler();
        if (HAL_OPAMP_Start(&hopamp1) != HAL_OK)
            Error_Handler();
        if (HAL_ADCEx_Calibration_Start(&DEMODULATOR_ADC_HANDLE, ADC_SINGLE_ENDED)
                != HAL_OK)
            Error_Handler();
    }

    // Initialize option bytes.
    FLASH_OBProgramInitTypeDef obInit = { 0 };
    HAL_FLASHEx_OBGetConfig(&obInit);

    if ((obInit.OptionType & OPTIONBYTE_USER) == RESET) {
        ERROR("FAIL: option byte init");
        Error_Handler();
    }

#if 1
    // Do not erase SRAM2 during reset.
    if ((obInit.USERConfig & FLASH_OPTR_SRAM2_RST) == RESET) {
        obInit.OptionType = OPTIONBYTE_USER;
        obInit.USERType = OB_USER_SRAM2_RST;
        obInit.USERConfig = FLASH_OPTR_SRAM2_RST;
        HAL_FLASH_OB_Unlock();
        HAL_FLASHEx_OBProgram(&obInit);
        HAL_FLASH_OB_Lock();
        HAL_FLASH_OB_Launch();
    }
#endif

#if 1
    // Enable hardware parity check on SRAM2
    HAL_FLASHEx_OBGetConfig(&obInit);
    if ((obInit.USERConfig & FLASH_OPTR_SRAM2_PE) == RESET) {
        obInit.OptionType = OPTIONBYTE_USER;
        obInit.USERType = OB_USER_SRAM2_PE;
        obInit.USERConfig = FLASH_OPTR_SRAM2_PE;
        HAL_FLASH_OB_Unlock();
        HAL_FLASHEx_OBProgram(&obInit);
        HAL_FLASH_OB_Lock();
        HAL_FLASH_OB_Launch();
    }
#endif

#if 1
    // Disable IWDG in stop2
    HAL_FLASHEx_OBGetConfig(&obInit);
    if ((obInit.USERConfig & FLASH_OPTR_IWDG_STOP)) {
        obInit.OptionType = OPTIONBYTE_USER;
        obInit.USERType = OB_USER_IWDG_STOP;
        obInit.USERConfig = OB_IWDG_STOP_FREEZE;
        HAL_FLASH_Unlock();
        HAL_FLASH_OB_Unlock();
        HAL_FLASHEx_OBProgram(&obInit);
        HAL_FLASH_OB_Launch();
        HAL_FLASH_OB_Lock();
        HAL_FLASH_Lock();
    }
    // Disable IWDG in shutdown
    HAL_FLASHEx_OBGetConfig(&obInit);
    if ((obInit.USERConfig & FLASH_OPTR_IWDG_STDBY)) {
        obInit.OptionType = OPTIONBYTE_USER;
        obInit.USERType = OB_USER_IWDG_STDBY;
        obInit.USERConfig = OB_IWDG_STDBY_FREEZE;
        HAL_FLASH_Unlock();
        HAL_FLASH_OB_Unlock();
        HAL_FLASHEx_OBProgram(&obInit);
        HAL_FLASH_OB_Launch();
        HAL_FLASH_OB_Lock();
        HAL_FLASH_Lock();
    }

#endif

#pragma GCC diagnostic push
#pragma GCC diagnostic ignored "-Wwrite-strings"    // cmsis-os is not const-correct.

    // At this point we start creating CMSIS-OS/FreeRTOS data structures.
    // Upon the first call to oxMutexCreate(), timers, and specifically
    // htim8, which is used for the LED indicator, stop working correctly
    // until the kernel starts. So we want to keep this section as short
    // and as quick as possible.

  /* USER CODE END 2 */

  /* USER CODE BEGIN RTOS_MUTEX */
  /* add mutexes, ... */

  // We want to acquire the mutex before the kernel starts. IOEventTask
  // expects it to be held when it starts and releases it after it has
  // read the configuration from EEPROM, when it is safe to initialize
  // the subsystems which depend on global configuration.

  /* USER CODE END RTOS_MUTEX */

  /* Create the timer(s) */
  /* definition and creation of usbShutdownTimer */
  osTimerStaticDef(usbShutdownTimer, usbShutdownTimerCallback, &usbShutdownTimerControlBlock);
  usbShutdownTimerHandle = osTimerCreate(osTimer(usbShutdownTimer), osTimerOnce, NULL);

  /* definition and creation of powerOffTimer */
  osTimerStaticDef(powerOffTimer, powerOffTimerCallback, &powerOffTimerControlBlock);
  powerOffTimerHandle = osTimerCreate(osTimer(powerOffTimer), osTimerOnce, NULL);

  /* definition and creation of batteryCheckTimer */
  osTimerStaticDef(batteryCheckTimer, batteryCheckCallback, &batteryCheckTimerControlBlock);
  batteryCheckTimerHandle = osTimerCreate(osTimer(batteryCheckTimer), osTimerPeriodic, NULL);

  /* Create the queue(s) */
  /* definition and creation of ioEventQueue */
  osMessageQStaticDef(ioEventQueue, 16, uint32_t, ioEventQueueBuffer, &ioEventQueueControlBlock);
  ioEventQueueHandle = osMessageCreate(osMessageQ(ioEventQueue), NULL);

  /* definition and creation of audioInputQueue */
  osMessageQStaticDef(audioInputQueue, 8, void*, audioInputQueueBuffer, &audioInputQueueControlBlock);
  audioInputQueueHandle = osMessageCreate(osMessageQ(audioInputQueue), NULL);

  /* definition and creation of hdlcInputQueue */
  osMessageQStaticDef(hdlcInputQueue, 3, uint32_t, hdlcInputQueueBuffer, &hdlcInputQueueControlBlock);
  hdlcInputQueueHandle = osMessageCreate(osMessageQ(hdlcInputQueue), NULL);

  /* definition and creation of hdlcOutputQueue */
  osMessageQStaticDef(hdlcOutputQueue, 8, uint32_t, hdlcOutputQueueBuffer, &hdlcOutputQueueControlBlock);
  hdlcOutputQueueHandle = osMessageCreate(osMessageQ(hdlcOutputQueue), NULL);

  /* definition and creation of dacOutputQueue */
  osMessageQStaticDef(dacOutputQueue, 128, uint8_t, dacOutputQueueBuffer, &dacOutputQueueControlBlock);
  dacOutputQueueHandle = osMessageCreate(osMessageQ(dacOutputQueue), NULL);

  /* definition and creation of adcInputQueue */
  osMessageQStaticDef(adcInputQueue, 3, void*, adcInputQueueBuffer, &adcInputQueueControlBlock);
  adcInputQueueHandle = osMessageCreate(osMessageQ(adcInputQueue), NULL);

  /* definition and creation of m17EncoderInputQueue */
  osMessageQStaticDef(m17EncoderInputQueue, 3, void*, m17EncoderInputQueueBuffer, &m17EncoderInputQueueControlBlock);
  m17EncoderInputQueueHandle = osMessageCreate(osMessageQ(m17EncoderInputQueue), NULL);

  /* USER CODE BEGIN RTOS_QUEUES */
  /* add queues, ... */
  /* definition and creation of digipeaterQueue */
  osMessageQStaticDef(digipeaterQueue, 8, uint32_t, digipeaterQueueBuffer, &digipeaterQueueControlBlock);
  digipeaterQueueHandle = osMessageCreate(osMessageQ(digipeaterQueue), NULL);

#pragma GCC diagnostic pop

  /* USER CODE END RTOS_QUEUES */

  /* Create the thread(s) */
  /* definition and creation of ioEventTask */
  osThreadStaticDef(ioEventTask, startIOEventTask, osPriorityLow, 0, 512, ioEventTaskBuffer, &ioEventTaskControlBlock);
  ioEventTaskHandle = osThreadCreate(osThread(ioEventTask), NULL);

  /* definition and creation of audioInputTask */
  osThreadStaticDef(audioInputTask, startAudioInputTask, osPriorityAboveNormal, 0, 512, audioInputTaskBuffer, &audioInputTaskControlBlock);
  audioInputTaskHandle = osThreadCreate(osThread(audioInputTask), NULL);

  /* definition and creation of modulatorTask */
  osThreadStaticDef(modulatorTask, startModulatorTask, osPriorityAboveNormal, 0, 384, modulatorTaskBuffer, &modulatorTaskControlBlock);
  modulatorTaskHandle = osThreadCreate(osThread(modulatorTask), NULL);

  /* USER CODE BEGIN RTOS_THREADS */
  /* add threads, ... */
  /* definition and creation of digipeaterTask */
  osThreadStaticDef(digipeaterTask, startDigipeaterTask, osPriorityNormal, 0, 256, digipeaterTaskBuffer, &digipeaterTaskControlBlock);
  digipeaterTaskHandle = osThreadCreate(osThread(digipeaterTask), NULL);
  osThreadSuspend(modulatorTaskHandle);
  osThreadSuspend(audioInputTaskHandle);

  /* USER CODE END RTOS_THREADS */

  /* Start scheduler */
  osKernelStart();

  /* We should never get here as control is now taken by the scheduler */

  /* Infinite loop */
  while (1)
  {

  }
}

void SystemClock_Config(void)
{
  RCC_OscInitTypeDef RCC_OscInitStruct = {0};
  RCC_ClkInitTypeDef RCC_ClkInitStruct = {0};

  /** Configure the main internal regulator output voltage
  */
  if (HAL_PWREx_ControlVoltageScaling(PWR_REGULATOR_VOLTAGE_SCALE1) != HAL_OK)
  {
    Error_Handler();
  }

  /** Configure LSE Drive Capability
  */
  HAL_PWR_EnableBkUpAccess();
  __HAL_RCC_LSEDRIVE_CONFIG(RCC_LSEDRIVE_LOW);

  /** Initializes the RCC Oscillators according to the specified parameters
  * in the RCC_OscInitTypeDef structure.
  */
  RCC_OscInitStruct.OscillatorType = RCC_OSCILLATORTYPE_HSI48|RCC_OSCILLATORTYPE_HSI
                              |RCC_OSCILLATORTYPE_LSI|RCC_OSCILLATORTYPE_LSE;
  RCC_OscInitStruct.LSEState = RCC_LSE_ON;
  RCC_OscInitStruct.HSIState = RCC_HSI_ON;
  RCC_OscInitStruct.HSI48State = RCC_HSI48_ON;
  RCC_OscInitStruct.HSICalibrationValue = RCC_HSICALIBRATION_DEFAULT;
  RCC_OscInitStruct.LSIState = RCC_LSI_ON;
  RCC_OscInitStruct.PLL.PLLState = RCC_PLL_NONE;
  if (HAL_RCC_OscConfig(&RCC_OscInitStruct) != HAL_OK)
  {
    Error_Handler();
  }

  /** Initializes the CPU, AHB and APB buses clocks
  */
  RCC_ClkInitStruct.ClockType = RCC_CLOCKTYPE_HCLK|RCC_CLOCKTYPE_SYSCLK
                              |RCC_CLOCKTYPE_PCLK1|RCC_CLOCKTYPE_PCLK2;
  RCC_ClkInitStruct.SYSCLKSource = RCC_SYSCLKSOURCE_HSI;
  RCC_ClkInitStruct.AHBCLKDivider = RCC_SYSCLK_DIV1;
  RCC_ClkInitStruct.APB1CLKDivider = RCC_HCLK_DIV1;
  RCC_ClkInitStruct.APB2CLKDivider = RCC_HCLK_DIV1;

  if (HAL_RCC_ClockConfig(&RCC_ClkInitStruct, FLASH_LATENCY_0) != HAL_OK)
  {
    Error_Handler();
  }
  HAL_RCC_MCOConfig(RCC_MCO1, RCC_MCO1SOURCE_SYSCLK, RCC_MCODIV_8);
}

void MX_ADC1_Init(void)
{

  ADC_MultiModeTypeDef multimode = {0};
  ADC_ChannelConfTypeDef sConfig = {0};

  /** Common config
  */
  hadc1.Instance = ADC1;
  hadc1.Init.ClockPrescaler = ADC_CLOCK_ASYNC_DIV1;
  hadc1.Init.Resolution = ADC_RESOLUTION_12B;
  hadc1.Init.DataAlign = ADC_DATAALIGN_RIGHT;
  hadc1.Init.ScanConvMode = ADC_SCAN_DISABLE;
  hadc1.Init.EOCSelection = ADC_EOC_SINGLE_CONV;
  hadc1.Init.LowPowerAutoWait = DISABLE;
  hadc1.Init.ContinuousConvMode = DISABLE;
  hadc1.Init.NbrOfConversion = 1;
  hadc1.Init.DiscontinuousConvMode = DISABLE;
  hadc1.Init.ExternalTrigConv = ADC_SOFTWARE_START;
  hadc1.Init.ExternalTrigConvEdge = ADC_EXTERNALTRIGCONVEDGE_NONE;
  hadc1.Init.DMAContinuousRequests = DISABLE;
  hadc1.Init.Overrun = ADC_OVR_DATA_PRESERVED;
  hadc1.Init.OversamplingMode = ENABLE;
  hadc1.Init.Oversampling.Ratio = ADC_OVERSAMPLING_RATIO_16;
  hadc1.Init.Oversampling.RightBitShift = ADC_RIGHTBITSHIFT_2;
  hadc1.Init.Oversampling.TriggeredMode = ADC_TRIGGEREDMODE_SINGLE_TRIGGER;
  hadc1.Init.Oversampling.OversamplingStopReset = ADC_REGOVERSAMPLING_CONTINUED_MODE;
  if (HAL_ADC_Init(&hadc1) != HAL_OK)
  {
    Error_Handler();
  }

  /** Configure the ADC multi-mode
  */
  multimode.Mode = ADC_MODE_INDEPENDENT;
  if (HAL_ADCEx_MultiModeConfigChannel(&hadc1, &multimode) != HAL_OK)
  {
    Error_Handler();
  }

  /** Configure Regular Channel
  */
  sConfig.Channel = ADC_CHANNEL_16;
  sConfig.Rank = ADC_REGULAR_RANK_1;
  sConfig.SamplingTime = ADC_SAMPLETIME_640CYCLES_5;
  sConfig.SingleDiff = ADC_SINGLE_ENDED;
  sConfig.OffsetNumber = ADC_OFFSET_NONE;
  sConfig.Offset = 0;
  if (HAL_ADC_ConfigChannel(&hadc1, &sConfig) != HAL_OK)
  {
    Error_Handler();
  }

}

void MX_ADC2_Init(void)
{

  ADC_ChannelConfTypeDef sConfig = {0};

  /** Common config
  */
  hadc2.Instance = ADC2;
  hadc2.Init.ClockPrescaler = ADC_CLOCK_ASYNC_DIV1;
  hadc2.Init.Resolution = ADC_RESOLUTION_12B;
  hadc2.Init.DataAlign = ADC_DATAALIGN_RIGHT;
  hadc2.Init.ScanConvMode = ADC_SCAN_DISABLE;
  hadc2.Init.EOCSelection = ADC_EOC_SINGLE_CONV;
  hadc2.Init.LowPowerAutoWait = DISABLE;
  hadc2.Init.ContinuousConvMode = DISABLE;
  hadc2.Init.NbrOfConversion = 1;
  hadc2.Init.DiscontinuousConvMode = DISABLE;
  hadc2.Init.ExternalTrigConv = ADC_EXTERNALTRIG_T6_TRGO;
  hadc2.Init.ExternalTrigConvEdge = ADC_EXTERNALTRIGCONVEDGE_RISING;
  hadc2.Init.DMAContinuousRequests = ENABLE;
  hadc2.Init.Overrun = ADC_OVR_DATA_PRESERVED;
  hadc2.Init.OversamplingMode = ENABLE;
  hadc2.Init.Oversampling.Ratio = ADC_OVERSAMPLING_RATIO_16;
  hadc2.Init.Oversampling.RightBitShift = ADC_RIGHTBITSHIFT_2;
  hadc2.Init.Oversampling.TriggeredMode = ADC_TRIGGEREDMODE_SINGLE_TRIGGER;
  hadc2.Init.Oversampling.OversamplingStopReset = ADC_REGOVERSAMPLING_CONTINUED_MODE;
  if (HAL_ADC_Init(&hadc2) != HAL_OK)
  {
    Error_Handler();
  }

  /** Configure Regular Channel
  */
  sConfig.Channel = ADC_CHANNEL_8;
  sConfig.Rank = ADC_REGULAR_RANK_1;
  sConfig.SamplingTime = ADC_SAMPLETIME_24CYCLES_5;
  sConfig.SingleDiff = ADC_SINGLE_ENDED;
  sConfig.OffsetNumber = ADC_OFFSET_NONE;
  sConfig.Offset = 0;
  if (HAL_ADC_ConfigChannel(&hadc2, &sConfig) != HAL_OK)
  {
    Error_Handler();
  }

}

void MX_COMP1_Init(void)
{

  hcomp1.Instance = COMP1;
  hcomp1.Init.InvertingInput = COMP_INPUT_MINUS_3_4VREFINT;
  hcomp1.Init.NonInvertingInput = COMP_INPUT_PLUS_IO2;
  hcomp1.Init.OutputPol = COMP_OUTPUTPOL_NONINVERTED;
  hcomp1.Init.Hysteresis = COMP_HYSTERESIS_LOW;
  hcomp1.Init.BlankingSrce = COMP_BLANKINGSRC_NONE;
  hcomp1.Init.Mode = COMP_POWERMODE_ULTRALOWPOWER;
  hcomp1.Init.WindowMode = COMP_WINDOWMODE_DISABLE;
  hcomp1.Init.TriggerMode = COMP_TRIGGERMODE_IT_FALLING;
  if (HAL_COMP_Init(&hcomp1) != HAL_OK)
  {
    Error_Handler();
  }

}

void MX_CRC_Init(void)
{

  hcrc.Instance = CRC;
  hcrc.Init.DefaultPolynomialUse = DEFAULT_POLYNOMIAL_DISABLE;
  hcrc.Init.DefaultInitValueUse = DEFAULT_INIT_VALUE_DISABLE;
  hcrc.Init.GeneratingPolynomial = 4129;
  hcrc.Init.CRCLength = CRC_POLYLENGTH_16B;
  hcrc.Init.InitValue = 0xFFFF;
  hcrc.Init.InputDataInversionMode = CRC_INPUTDATA_INVERSION_BYTE;
  hcrc.Init.OutputDataInversionMode = CRC_OUTPUTDATA_INVERSION_DISABLE;
  hcrc.InputDataFormat = CRC_INPUTDATA_FORMAT_BYTES;
  if (HAL_CRC_Init(&hcrc) != HAL_OK)
  {
    Error_Handler();
  }

}

void MX_DAC1_Init(void)
{

  DAC_ChannelConfTypeDef sConfig = {0};

  /** DAC Initialization
  */
  hdac1.Instance = DAC1;
  if (HAL_DAC_Init(&hdac1) != HAL_OK)
  {
    Error_Handler();
  }

  /** DAC channel OUT1 config
  */
  sConfig.DAC_SampleAndHold = DAC_SAMPLEANDHOLD_DISABLE;
  sConfig.DAC_Trigger = DAC_TRIGGER_T7_TRGO;
  sConfig.DAC_OutputBuffer = DAC_OUTPUTBUFFER_ENABLE;
  sConfig.DAC_ConnectOnChipPeripheral = DAC_CHIPCONNECT_DISABLE;
  sConfig.DAC_UserTrimming = DAC_TRIMMING_FACTORY;
  if (HAL_DAC_ConfigChannel(&hdac1, &sConfig, DAC_CHANNEL_1) != HAL_OK)
  {
    Error_Handler();
  }

  /** DAC channel OUT2 config
  */
  sConfig.DAC_Trigger = DAC_TRIGGER_NONE;
  if (HAL_DAC_ConfigChannel(&hdac1, &sConfig, DAC_CHANNEL_2) != HAL_OK)
  {
    Error_Handler();
  }

}

void MX_I2C1_Init(void)
{

  hi2c1.Instance = I2C1;
  hi2c1.Init.Timing = 0x00000107;
  hi2c1.Init.OwnAddress1 = 0;
  hi2c1.Init.AddressingMode = I2C_ADDRESSINGMODE_7BIT;
  hi2c1.Init.DualAddressMode = I2C_DUALADDRESS_DISABLE;
  hi2c1.Init.OwnAddress2 = 0;
  hi2c1.Init.OwnAddress2Masks = I2C_OA2_NOMASK;
  hi2c1.Init.GeneralCallMode = I2C_GENERALCALL_DISABLE;
  hi2c1.Init.NoStretchMode = I2C_NOSTRETCH_DISABLE;
  if (HAL_I2C_Init(&hi2c1) != HAL_OK)
  {
    Error_Handler();
  }

  /** Configure Analogue filter
  */
  if (HAL_I2CEx_ConfigAnalogFilter(&hi2c1, I2C_ANALOGFILTER_ENABLE) != HAL_OK)
  {
    Error_Handler();
  }

  /** Configure Digital filter
  */
  if (HAL_I2CEx_ConfigDigitalFilter(&hi2c1, 0) != HAL_OK)
  {
    Error_Handler();
  }

  /** I2C Fast mode Plus enable
  */
  HAL_I2CEx_EnableFastModePlus(I2C_FASTMODEPLUS_I2C1);

}

void MX_IWDG_Init(void)
{

  hiwdg.Instance = IWDG;
  hiwdg.Init.Prescaler = IWDG_PRESCALER_64;
  hiwdg.Init.Window = 4095;
  hiwdg.Init.Reload = 4095;
  if (HAL_IWDG_Init(&hiwdg) != HAL_OK)
  {
    Error_Handler();
  }

}

void MX_OPAMP1_Init(void)
{

  hopamp1.Instance = OPAMP1;
  hopamp1.Init.PowerSupplyRange = OPAMP_POWERSUPPLY_HIGH;
  hopamp1.Init.Mode = OPAMP_PGA_MODE;
  hopamp1.Init.NonInvertingInput = OPAMP_NONINVERTINGINPUT_IO0;
  hopamp1.Init.InvertingInput = OPAMP_INVERTINGINPUT_CONNECT_NO;
  hopamp1.Init.PgaGain = OPAMP_PGA_GAIN_2;
  hopamp1.Init.PowerMode = OPAMP_POWERMODE_NORMALPOWER;
  hopamp1.Init.UserTrimming = OPAMP_TRIMMING_FACTORY;
  if (HAL_OPAMP_Init(&hopamp1) != HAL_OK)
  {
    Error_Handler();
  }

}

void MX_OPAMP2_Init(void)
{

  hopamp2.Instance = OPAMP2;
  hopamp2.Init.PowerSupplyRange = OPAMP_POWERSUPPLY_HIGH;
  hopamp2.Init.Mode = OPAMP_STANDALONE_MODE;
  hopamp2.Init.NonInvertingInput = OPAMP_NONINVERTINGINPUT_IO0;
  hopamp2.Init.InvertingInput = OPAMP_INVERTINGINPUT_IO0;
  hopamp2.Init.PowerMode = OPAMP_POWERMODE_NORMALPOWER;
  hopamp2.Init.UserTrimming = OPAMP_TRIMMING_FACTORY;
  if (HAL_OPAMP_Init(&hopamp2) != HAL_OK)
  {
    Error_Handler();
  }

}

void MX_RNG_Init(void)
{

  hrng.Instance = RNG;
  hrng.Init.ClockErrorDetection = RNG_CED_ENABLE;
  if (HAL_RNG_Init(&hrng) != HAL_OK)
  {
    Error_Handler();
  }
  /* USER CODE BEGIN RNG_Init 2 */

  // Code from STM because the HAL is broken for this chip.
  // https://community.st.com/s/feed/0D53W00000jn7SESAY?t=1619830545851

#define RNG_MAGIC_NUMBER       0x17590ABC  /* Magic Number */
#define RNG_HTCR_VAL           0x0000AA74  /* HTCR Value */

    __IO uint32_t  HTCR_VALUE=0;
    //put this after the RNG initializition and before the infinite loop
    RNG->CR = 0x40F00D40; // config A
    HAL_Delay(20);
    /* RNG HTCR value setting 0xAA74 */
    /*!< magic number must be written immediately before to RNG_HTCRG */
    RNG->HTCR = RNG_MAGIC_NUMBER;
    RNG->HTCR = RNG_HTCR_VAL;
    HTCR_VALUE = 0 ;
    RNG->HTCR = RNG_MAGIC_NUMBER;
    HTCR_VALUE = RNG->HTCR;
    RNG->HTCR = RNG_MAGIC_NUMBER;
    while ( HTCR_VALUE != RNG_HTCR_VAL); // check that HTCR value is correctly set
    RNG->CR = 0x00F00D4C; // config A + RNG EN =1, IE=1
    HAL_Delay(1); /* a delay to wait for CONDRST to take effect */

  /* USER CODE END RNG_Init 2 */

}

void MX_RTC_Init(void)
{

  RTC_TimeTypeDef sTime = {0};
  RTC_DateTypeDef sDate = {0};

  /** Initialize RTC Only
  */
  hrtc.Instance = RTC;
  hrtc.Init.HourFormat = RTC_HOURFORMAT_24;
  hrtc.Init.AsynchPrediv = 127;
  hrtc.Init.SynchPrediv = 255;
  hrtc.Init.OutPut = RTC_OUTPUT_DISABLE;
  hrtc.Init.OutPutRemap = RTC_OUTPUT_REMAP_NONE;
  hrtc.Init.OutPutPolarity = RTC_OUTPUT_POLARITY_HIGH;
  hrtc.Init.OutPutType = RTC_OUTPUT_TYPE_OPENDRAIN;
  hrtc.Init.BinMode = RTC_BINARY_NONE;
  if (HAL_RTC_Init(&hrtc) != HAL_OK)
  {
    Error_Handler();
  }

  /* USER CODE BEGIN Check_RTC_BKUP */
    // Do not initialize RTC if the date/time has been set.
    if (!(RTC->ICSR & 0x10)) {

  /* USER CODE END Check_RTC_BKUP */

  /** Initialize RTC and set the Time and Date
  */
  sTime.Hours = 0x0;
  sTime.Minutes = 0x0;
  sTime.Seconds = 0x0;
  sTime.DayLightSaving = RTC_DAYLIGHTSAVING_NONE;
  sTime.StoreOperation = RTC_STOREOPERATION_RESET;
  if (HAL_RTC_SetTime(&hrtc, &sTime, RTC_FORMAT_BCD) != HAL_OK)
  {
    Error_Handler();
  }
  sDate.WeekDay = RTC_WEEKDAY_MONDAY;
  sDate.Month = RTC_MONTH_JANUARY;
  sDate.Date = 0x1;
  sDate.Year = 0x0;

  if (HAL_RTC_SetDate(&hrtc, &sDate, RTC_FORMAT_BCD) != HAL_OK)
  {
    Error_Handler();
  }
    }

}

void MX_TIM4_Init(void)
{

  TIM_ClockConfigTypeDef sClockSourceConfig = {0};
  TIM_MasterConfigTypeDef sMasterConfig = {0};

  htim4.Instance = TIM4;
  htim4.Init.Prescaler = 32;
  htim4.Init.CounterMode = TIM_COUNTERMODE_UP;
  htim4.Init.Period = 15624;
  htim4.Init.ClockDivision = TIM_CLOCKDIVISION_DIV1;
  htim4.Init.AutoReloadPreload = TIM_AUTORELOAD_PRELOAD_DISABLE;
  if (HAL_TIM_Base_Init(&htim4) != HAL_OK)
  {
    Error_Handler();
  }
  sClockSourceConfig.ClockSource = TIM_CLOCKSOURCE_INTERNAL;
  if (HAL_TIM_ConfigClockSource(&htim4, &sClockSourceConfig) != HAL_OK)
  {
    Error_Handler();
  }
  sMasterConfig.MasterOutputTrigger = TIM_TRGO_UPDATE;
  sMasterConfig.MasterSlaveMode = TIM_MASTERSLAVEMODE_DISABLE;
  if (HAL_TIMEx_MasterConfigSynchronization(&htim4, &sMasterConfig) != HAL_OK)
  {
    Error_Handler();
  }

}

void MX_TIM6_Init(void)
{

  TIM_MasterConfigTypeDef sMasterConfig = {0};

  htim6.Instance = TIM6;
  htim6.Init.Prescaler = 0;
  htim6.Init.CounterMode = TIM_COUNTERMODE_UP;
  htim6.Init.Period = 2499;
  htim6.Init.AutoReloadPreload = TIM_AUTORELOAD_PRELOAD_DISABLE;
  if (HAL_TIM_Base_Init(&htim6) != HAL_OK)
  {
    Error_Handler();
  }
  sMasterConfig.MasterOutputTrigger = TIM_TRGO_UPDATE;
  sMasterConfig.MasterSlaveMode = TIM_MASTERSLAVEMODE_DISABLE;
  if (HAL_TIMEx_MasterConfigSynchronization(&htim6, &sMasterConfig) != HAL_OK)
  {
    Error_Handler();
  }

}

void MX_TIM7_Init(void)
{

  TIM_MasterConfigTypeDef sMasterConfig = {0};

  htim7.Instance = TIM7;
  htim7.Init.Prescaler = 0;
  htim7.Init.CounterMode = TIM_COUNTERMODE_UP;
  htim7.Init.Period = 2499;
  htim7.Init.AutoReloadPreload = TIM_AUTORELOAD_PRELOAD_DISABLE;
  if (HAL_TIM_Base_Init(&htim7) != HAL_OK)
  {
    Error_Handler();
  }
  sMasterConfig.MasterOutputTrigger = TIM_TRGO_UPDATE;
  sMasterConfig.MasterSlaveMode = TIM_MASTERSLAVEMODE_DISABLE;
  if (HAL_TIMEx_MasterConfigSynchronization(&htim7, &sMasterConfig) != HAL_OK)
  {
    Error_Handler();
  }

}

void MX_TIM8_Init(void)
{

  TIM_ClockConfigTypeDef sClockSourceConfig = {0};
  TIM_MasterConfigTypeDef sMasterConfig = {0};
  TIM_OC_InitTypeDef sConfigOC = {0};
  TIM_BreakDeadTimeConfigTypeDef sBreakDeadTimeConfig = {0};

  htim8.Instance = TIM8;
  htim8.Init.Prescaler = 15;
  htim8.Init.CounterMode = TIM_COUNTERMODE_UP;
  htim8.Init.Period = 9999;
  htim8.Init.ClockDivision = TIM_CLOCKDIVISION_DIV1;
  htim8.Init.RepetitionCounter = 0;
  htim8.Init.AutoReloadPreload = TIM_AUTORELOAD_PRELOAD_DISABLE;
  if (HAL_TIM_Base_Init(&htim8) != HAL_OK)
  {
    Error_Handler();
  }
  sClockSourceConfig.ClockSource = TIM_CLOCKSOURCE_INTERNAL;
  if (HAL_TIM_ConfigClockSource(&htim8, &sClockSourceConfig) != HAL_OK)
  {
    Error_Handler();
  }
  if (HAL_TIM_PWM_Init(&htim8) != HAL_OK)
  {
    Error_Handler();
  }
  sMasterConfig.MasterOutputTrigger = TIM_TRGO_RESET;
  sMasterConfig.MasterOutputTrigger2 = TIM_TRGO2_RESET;
  sMasterConfig.MasterSlaveMode = TIM_MASTERSLAVEMODE_DISABLE;
  if (HAL_TIMEx_MasterConfigSynchronization(&htim8, &sMasterConfig) != HAL_OK)
  {
    Error_Handler();
  }
  sConfigOC.OCMode = TIM_OCMODE_PWM1;
  sConfigOC.Pulse = 0;
  sConfigOC.OCPolarity = TIM_OCPOLARITY_LOW;
  sConfigOC.OCNPolarity = TIM_OCNPOLARITY_HIGH;
  sConfigOC.OCFastMode = TIM_OCFAST_DISABLE;
  sConfigOC.OCIdleState = TIM_OCIDLESTATE_SET;
  sConfigOC.OCNIdleState = TIM_OCNIDLESTATE_RESET;
  if (HAL_TIM_PWM_ConfigChannel(&htim8, &sConfigOC, TIM_CHANNEL_1) != HAL_OK)
  {
    Error_Handler();
  }
  if (HAL_TIM_PWM_ConfigChannel(&htim8, &sConfigOC, TIM_CHANNEL_2) != HAL_OK)
  {
    Error_Handler();
  }
  if (HAL_TIM_PWM_ConfigChannel(&htim8, &sConfigOC, TIM_CHANNEL_3) != HAL_OK)
  {
    Error_Handler();
  }
  sBreakDeadTimeConfig.OffStateRunMode = TIM_OSSR_DISABLE;
  sBreakDeadTimeConfig.OffStateIDLEMode = TIM_OSSI_DISABLE;
  sBreakDeadTimeConfig.LockLevel = TIM_LOCKLEVEL_OFF;
  sBreakDeadTimeConfig.DeadTime = 0;
  sBreakDeadTimeConfig.BreakState = TIM_BREAK_DISABLE;
  sBreakDeadTimeConfig.BreakPolarity = TIM_BREAKPOLARITY_HIGH;
  sBreakDeadTimeConfig.BreakFilter = 0;
  sBreakDeadTimeConfig.Break2State = TIM_BREAK2_DISABLE;
  sBreakDeadTimeConfig.Break2Polarity = TIM_BREAK2POLARITY_HIGH;
  sBreakDeadTimeConfig.Break2Filter = 0;
  sBreakDeadTimeConfig.AutomaticOutput = TIM_AUTOMATICOUTPUT_DISABLE;
  if (HAL_TIMEx_ConfigBreakDeadTime(&htim8, &sBreakDeadTimeConfig) != HAL_OK)
  {
    Error_Handler();
  }
  HAL_TIM_MspPostInit(&htim8);

}

void MX_USART3_UART_Init(void)
{

  huart3.Instance = USART3;
  huart3.Init.BaudRate = 115200;
  huart3.Init.WordLength = UART_WORDLENGTH_8B;
  huart3.Init.StopBits = UART_STOPBITS_1;
  huart3.Init.Parity = UART_PARITY_NONE;
  huart3.Init.Mode = UART_MODE_TX_RX;
  huart3.Init.HwFlowCtl = UART_HWCONTROL_RTS_CTS;
  huart3.Init.OverSampling = UART_OVERSAMPLING_16;
  huart3.Init.OneBitSampling = UART_ONE_BIT_SAMPLE_DISABLE;
  huart3.Init.ClockPrescaler = UART_PRESCALER_DIV1;
  huart3.AdvancedInit.AdvFeatureInit = UART_ADVFEATURE_NO_INIT;
  if (HAL_UART_Init(&huart3) != HAL_OK)
  {
    Error_Handler();
  }
  if (HAL_UARTEx_SetTxFifoThreshold(&huart3, UART_TXFIFO_THRESHOLD_1_8) != HAL_OK)
  {
    Error_Handler();
  }
  if (HAL_UARTEx_SetRxFifoThreshold(&huart3, UART_RXFIFO_THRESHOLD_1_8) != HAL_OK)
  {
    Error_Handler();
  }
  if (HAL_UARTEx_EnableFifoMode(&huart3) != HAL_OK)
  {
    Error_Handler();
  }

}

void MX_DMA_Init(void)
{

  /* DMA controller clock enable */
  __HAL_RCC_DMAMUX1_CLK_ENABLE();
  __HAL_RCC_DMA1_CLK_ENABLE();

  /* DMA interrupt init */
  /* DMA1_Channel1_IRQn interrupt configuration */
  HAL_NVIC_SetPriority(DMA1_Channel1_IRQn, 5, 0);
  HAL_NVIC_EnableIRQ(DMA1_Channel1_IRQn);
  /* DMA1_Channel2_IRQn interrupt configuration */
  HAL_NVIC_SetPriority(DMA1_Channel2_IRQn, 5, 0);
  HAL_NVIC_EnableIRQ(DMA1_Channel2_IRQn);
  /* DMA1_Channel3_IRQn interrupt configuration */
  HAL_NVIC_SetPriority(DMA1_Channel3_IRQn, 5, 0);
  HAL_NVIC_EnableIRQ(DMA1_Channel3_IRQn);
  /* DMA1_Channel4_IRQn interrupt configuration */
  HAL_NVIC_SetPriority(DMA1_Channel4_IRQn, 5, 0);
  HAL_NVIC_EnableIRQ(DMA1_Channel4_IRQn);
  /* DMA1_Channel5_IRQn interrupt configuration */
  HAL_NVIC_SetPriority(DMA1_Channel5_IRQn, 5, 0);
  HAL_NVIC_EnableIRQ(DMA1_Channel5_IRQn);
  /* DMA1_Channel6_IRQn interrupt configuration */
  HAL_NVIC_SetPriority(DMA1_Channel6_IRQn, 5, 0);
  HAL_NVIC_EnableIRQ(DMA1_Channel6_IRQn);
  /* DMAMUX1_OVR_IRQn interrupt configuration */
  HAL_NVIC_SetPriority(DMAMUX1_OVR_IRQn, 5, 0);
  HAL_NVIC_EnableIRQ(DMAMUX1_OVR_IRQn);

}

void MX_GPIO_Init(void)
{
  GPIO_InitTypeDef GPIO_InitStruct = {0};

  /* GPIO Ports Clock Enable */
  __HAL_RCC_GPIOC_CLK_ENABLE();
  __HAL_RCC_GPIOH_CLK_ENABLE();
  __HAL_RCC_GPIOA_CLK_ENABLE();
  __HAL_RCC_GPIOB_CLK_ENABLE();
  __HAL_RCC_GPIOD_CLK_ENABLE();

  /*Configure GPIO pin Output Level */
  HAL_GPIO_WritePin(TCXO_EN_GPIO_Port, TCXO_EN_Pin, GPIO_PIN_RESET);

  /*Configure GPIO pin Output Level */
  HAL_GPIO_WritePin(GPIOC, BT_CMD2_Pin|BT_CMD3_Pin|AUDIO_ATTEN_Pin, GPIO_PIN_SET);

  /*Configure GPIO pin Output Level */
  HAL_GPIO_WritePin(GPIOB, BAT_DIV_Pin|BAT_CE_Pin|BT_CMD1_Pin|BT_RESET_Pin, GPIO_PIN_SET);

  /*Configure GPIO pin Output Level */
  HAL_GPIO_WritePin(GPIOB, PTT_B_Pin|PTT_A_Pin, GPIO_PIN_RESET);

  /*Configure GPIO pin Output Level */
  HAL_GPIO_WritePin(GPIOC, VDD_EN_Pin|BT_WAKE_Pin, GPIO_PIN_RESET);

  /*Configure GPIO pin Output Level */
  HAL_GPIO_WritePin(BT_SLEEP_GPIO_Port, BT_SLEEP_Pin, GPIO_PIN_RESET);

  /*Configure GPIO pins : VDD_SENSE_Pin BT_STATE1_Pin BT_STATE2_Pin SW_POWER_Pin */
  GPIO_InitStruct.Pin = VDD_SENSE_Pin|BT_STATE1_Pin|BT_STATE2_Pin|SW_POWER_Pin;
  GPIO_InitStruct.Mode = GPIO_MODE_IT_RISING_FALLING;
  GPIO_InitStruct.Pull = GPIO_NOPULL;
  HAL_GPIO_Init(GPIOC, &GPIO_InitStruct);

  /*Configure GPIO pin : TCXO_EN_Pin */
  GPIO_InitStruct.Pin = TCXO_EN_Pin;
  GPIO_InitStruct.Mode = GPIO_MODE_OUTPUT_PP;
  GPIO_InitStruct.Pull = GPIO_NOPULL;
  GPIO_InitStruct.Speed = GPIO_SPEED_FREQ_LOW;
  HAL_GPIO_Init(TCXO_EN_GPIO_Port, &GPIO_InitStruct);

  /*Configure GPIO pins : BT_CMD2_Pin BT_CMD3_Pin AUDIO_ATTEN_Pin BT_WAKE_Pin */
  GPIO_InitStruct.Pin = BT_CMD2_Pin|BT_CMD3_Pin|AUDIO_ATTEN_Pin|BT_WAKE_Pin;
  GPIO_InitStruct.Mode = GPIO_MODE_OUTPUT_OD;
  GPIO_InitStruct.Pull = GPIO_NOPULL;
  GPIO_InitStruct.Speed = GPIO_SPEED_FREQ_LOW;
  HAL_GPIO_Init(GPIOC, &GPIO_InitStruct);

  /*Configure GPIO pins : PA1_Pin PA10 */
  GPIO_InitStruct.Pin = PA1_Pin|GPIO_PIN_10;
  GPIO_InitStruct.Mode = GPIO_MODE_ANALOG;
  GPIO_InitStruct.Pull = GPIO_NOPULL;
  HAL_GPIO_Init(GPIOA, &GPIO_InitStruct);

  /*Configure GPIO pins : OVP_ERROR_Pin VUSB_SENSE_Pin */
  GPIO_InitStruct.Pin = OVP_ERROR_Pin|VUSB_SENSE_Pin;
  GPIO_InitStruct.Mode = GPIO_MODE_IT_RISING_FALLING;
  GPIO_InitStruct.Pull = GPIO_NOPULL;
  HAL_GPIO_Init(GPIOA, &GPIO_InitStruct);

  /*Configure GPIO pins : PB10_Pin PB12_Pin PB7 */
  GPIO_InitStruct.Pin = PB10_Pin|PB12_Pin|GPIO_PIN_7;
  GPIO_InitStruct.Mode = GPIO_MODE_ANALOG;
  GPIO_InitStruct.Pull = GPIO_NOPULL;
  HAL_GPIO_Init(GPIOB, &GPIO_InitStruct);

  /*Configure GPIO pins : BAT_DIV_Pin BAT_CE_Pin BT_CMD1_Pin BT_RESET_Pin */
  GPIO_InitStruct.Pin = BAT_DIV_Pin|BAT_CE_Pin|BT_CMD1_Pin|BT_RESET_Pin;
  GPIO_InitStruct.Mode = GPIO_MODE_OUTPUT_OD;
  GPIO_InitStruct.Pull = GPIO_NOPULL;
  GPIO_InitStruct.Speed = GPIO_SPEED_FREQ_LOW;
  HAL_GPIO_Init(GPIOB, &GPIO_InitStruct);

  /*Configure GPIO pins : PTT_B_Pin PTT_A_Pin */
  GPIO_InitStruct.Pin = PTT_B_Pin|PTT_A_Pin;
  GPIO_InitStruct.Mode = GPIO_MODE_OUTPUT_PP;
  GPIO_InitStruct.Pull = GPIO_NOPULL;
  GPIO_InitStruct.Speed = GPIO_SPEED_FREQ_LOW;
  HAL_GPIO_Init(GPIOB, &GPIO_InitStruct);

  /*Configure GPIO pin : VDD_EN_Pin */
  GPIO_InitStruct.Pin = VDD_EN_Pin;
  GPIO_InitStruct.Mode = GPIO_MODE_OUTPUT_PP;
  GPIO_InitStruct.Pull = GPIO_NOPULL;
  GPIO_InitStruct.Speed = GPIO_SPEED_FREQ_LOW;
  HAL_GPIO_Init(VDD_EN_GPIO_Port, &GPIO_InitStruct);

  /*Configure GPIO pin : PA8 */
  GPIO_InitStruct.Pin = GPIO_PIN_8;
  GPIO_InitStruct.Mode = GPIO_MODE_AF_PP;
  GPIO_InitStruct.Pull = GPIO_NOPULL;
  GPIO_InitStruct.Speed = GPIO_SPEED_FREQ_LOW;
  GPIO_InitStruct.Alternate = GPIO_AF0_MCO;
  HAL_GPIO_Init(GPIOA, &GPIO_InitStruct);

  /*Configure GPIO pin : BT_SLEEP_Pin */
  GPIO_InitStruct.Pin = BT_SLEEP_Pin;
  GPIO_InitStruct.Mode = GPIO_MODE_OUTPUT_PP;
  GPIO_InitStruct.Pull = GPIO_NOPULL;
  GPIO_InitStruct.Speed = GPIO_SPEED_FREQ_LOW;
  HAL_GPIO_Init(BT_SLEEP_GPIO_Port, &GPIO_InitStruct);

  /*Configure GPIO pin : SW_BOOT_Pin */
  GPIO_InitStruct.Pin = SW_BOOT_Pin;
  GPIO_InitStruct.Mode = GPIO_MODE_IT_RISING;
  GPIO_InitStruct.Pull = GPIO_NOPULL;
  HAL_GPIO_Init(SW_BOOT_GPIO_Port, &GPIO_InitStruct);

}

/* USER CODE BEGIN 4 */

#if 1
_ssize_t _write_r(struct _reent *r, int fd, const void *ptr, size_t len);

_ssize_t _write_r(struct _reent *r, int fd, const void *ptr, size_t len)
{
  UNUSED(r);
  UNUSED(fd);
#ifdef KISS_LOGGING
    for (size_t i = 0; i != len; ++i)
      ITM_SendChar(((char*) ptr)[i]);
#endif
  return len;
}

int _write(int file, char *ptr, int len);

int _write(int file, char *ptr, int len) {
    UNUSED(file);
#ifdef KISS_LOGGING
    for (int i = 0; i != len; ++i)
      ITM_SendChar(ptr[i]);
#endif
    return len;

}
#endif

void init_rtc_date_time()
{
    if (READ_REG(BKUP_BT_EEPROM_CRC) != 0) return;

    RTC_TimeTypeDef sTime;
    RTC_DateTypeDef sDate;

    /**Initialize RTC and set the Time and Date
    */
  sTime.Hours = 0x0;
  sTime.Minutes = 0x0;
  sTime.Seconds = 0x0;
  sTime.DayLightSaving = RTC_DAYLIGHTSAVING_NONE;
  sTime.StoreOperation = RTC_STOREOPERATION_RESET;
  sTime.TimeFormat = RTC_HOURFORMAT_24;
  if (HAL_RTC_SetTime(&hrtc, &sTime, RTC_FORMAT_BCD) != HAL_OK)
  {
    _Error_Handler(__FILE_NAME__, __LINE__);
  }

  sDate.WeekDay = RTC_WEEKDAY_MONDAY;
  sDate.Month = RTC_MONTH_JANUARY;
  sDate.Date = 0x1;
  sDate.Year = 0x0;

  if (HAL_RTC_SetDate(&hrtc, &sDate, RTC_FORMAT_BCD) != HAL_OK)
  {
    _Error_Handler(__FILE_NAME__, __LINE__);
  }
}

void init_rtc_alarm()
{
    RTC_AlarmTypeDef sAlarm;

    /**Enable the Alarm A
    */
  sAlarm.AlarmTime.Hours = 0x0;
  sAlarm.AlarmTime.Minutes = 0x0;
  sAlarm.AlarmTime.Seconds = 0x0;
  sAlarm.AlarmTime.SubSeconds = 0x0;
  sAlarm.AlarmTime.DayLightSaving = RTC_DAYLIGHTSAVING_NONE;
  sAlarm.AlarmTime.StoreOperation = RTC_STOREOPERATION_RESET;
  sAlarm.AlarmMask = RTC_ALARMMASK_NONE;
  sAlarm.AlarmSubSecondMask = RTC_ALARMSUBSECONDMASK_ALL;
  sAlarm.AlarmDateWeekDaySel = RTC_ALARMDATEWEEKDAYSEL_DATE;
  sAlarm.AlarmDateWeekDay = 0x1;
  sAlarm.Alarm = RTC_ALARM_A;
  if (HAL_RTC_SetAlarm(&hrtc, &sAlarm, RTC_FORMAT_BCD) != HAL_OK)
  {
    _Error_Handler(__FILE_NAME__, __LINE__);
  }

    /**Enable the Alarm B
    */
  sAlarm.AlarmDateWeekDay = 0x1;
  sAlarm.Alarm = RTC_ALARM_B;

}

/**
  * @brief System Clock Configuration
  * @retval None
  */
void SysClock2(void)
{
    RCC_OscInitTypeDef RCC_OscInitStruct = {0};
    RCC_ClkInitTypeDef RCC_ClkInitStruct = {0};

    if (HAL_RCC_GetHCLKFreq() == 2000000)
        return;

    INFO("Setting 2MHz SysClock.");

    vTaskSuspendAll();

    HAL_PWREx_DisableLowPowerRunMode();

    /** Configure the main internal regulator output voltage
     */
    if (HAL_PWREx_ControlVoltageScaling(PWR_REGULATOR_VOLTAGE_SCALE1) != HAL_OK) {
        Error_Handler();
    }

    RCC_ClkInitStruct.ClockType = RCC_CLOCKTYPE_SYSCLK;
    RCC_ClkInitStruct.SYSCLKSource = RCC_SYSCLKSOURCE_HSI;

    // Use HSI for SysClock while reconfiguring clocks.
    if (HAL_RCC_ClockConfig(&RCC_ClkInitStruct, FLASH_LATENCY_0) != HAL_OK) {
        _Error_Handler(__FILE_NAME__, __LINE__);
    }

    // Configure the Systick interrupt time
    HAL_SYSTICK_Config(HAL_RCC_GetHCLKFreq() / 1000);

    TPI->ACPR = 7; // 16MHz

    __HAL_RCC_PLL_DISABLE(); // Work around HAL_RCC_OscConfig bug.

    // Disable HSE, enable MSI and set to 2MHz, disable PLL.
    RCC_OscInitStruct.OscillatorType = RCC_OSCILLATORTYPE_MSI | RCC_OSCILLATORTYPE_HSE | RCC_OSCILLATORTYPE_LSE;
    RCC_OscInitStruct.LSEState = RCC_LSE_ON_RTC_ONLY;
    RCC_OscInitStruct.HSEState = RCC_HSE_OFF;
    RCC_OscInitStruct.MSIState = RCC_MSI_ON;
    RCC_OscInitStruct.MSICalibrationValue = 0;
    RCC_OscInitStruct.MSIClockRange = RCC_MSIRANGE_5;
    RCC_OscInitStruct.PLL.PLLState = RCC_PLL_OFF;
    RCC_OscInitStruct.PLL.PLLSource = RCC_PLLSOURCE_HSI;

    HAL_StatusTypeDef result = HAL_RCC_OscConfig(&RCC_OscInitStruct);
    if (result != HAL_OK)
    {
        ERROR("HAL_RCC_OscConfig = %d", result);
        _Error_Handler2(__FILE_NAME__, __LINE__, result);
    }

    // Set SysClock to MSI.
    RCC_ClkInitStruct.ClockType = RCC_CLOCKTYPE_SYSCLK;
    RCC_ClkInitStruct.SYSCLKSource = RCC_SYSCLKSOURCE_MSI;

    result = HAL_RCC_ClockConfig(&RCC_ClkInitStruct, FLASH_LATENCY_0);
    if (result != HAL_OK)
    {
        ERROR("HAL_RCC_ClockConfig = %d", result);
        _Error_Handler2(__FILE_NAME__, __LINE__, result);
    }

    // Unusable when LSE is not driven externally.
    // HAL_RCCEx_EnableMSIPLLMode();

    // Set voltage regulators to lowest power mode.
    if (HAL_PWREx_ControlVoltageScaling(PWR_REGULATOR_VOLTAGE_SCALE2) != HAL_OK) {
        Error_Handler();
    }

    HAL_PWREx_EnableLowPowerRunMode();

    // Disable TCXO.
    HAL_GPIO_WritePin(TCXO_EN_GPIO_Port, TCXO_EN_Pin, GPIO_PIN_RESET);

    TPI->ACPR = 0;
    __HAL_TIM_SET_PRESCALER(&LED_PWM_TIMER_HANDLE, 1);
    update_power_monitor_timer();

    // Configure the Systick interrupt time
    HAL_SYSTICK_Config(HAL_RCC_GetHCLKFreq() / 1000);

    xTaskResumeAll();

    INFO("CPU core clock: %luHz", SystemCoreClock);

#if defined(DEBUG)
    HAL_RCC_MCOConfig(RCC_MCO1, RCC_MCO1SOURCE_MSI, RCC_MCODIV_1);
#else
    HAL_RCC_MCOConfig(RCC_MCO1, RCC_MCO1SOURCE_NOCLOCK, RCC_MCODIV_1);
#endif
}

void SysClock48()
{
    RCC_OscInitTypeDef RCC_OscInitStruct = {0};
    RCC_ClkInitTypeDef RCC_ClkInitStruct = {0};

    if (__HAL_RCC_GET_PLL_OSCSOURCE() == RCC_PLLSOURCE_HSE && HAL_RCC_GetHCLKFreq() == 48000000) return;

    INFO("Setting 48MHz SysClock.");

    // VDD must be enabled to use TCXO.
    if (!(VDD_EN_GPIO_Port->ODR & VDD_EN_Pin)) {
        _Error_Handler(__FILE_NAME__, __LINE__);
    }

    // Enable TCXO. The ECS-TXO-2520 has a start-up time of 10ms.
    HAL_GPIO_WritePin(TCXO_EN_GPIO_Port, TCXO_EN_Pin, GPIO_PIN_SET);

    DELAY(10);

    vTaskSuspendAll();

    // Set voltage regulator to normal run mode.
    HAL_PWREx_DisableLowPowerRunMode();
    HAL_RCCEx_DisableMSIPLLMode();
    if (HAL_PWREx_ControlVoltageScaling(PWR_REGULATOR_VOLTAGE_SCALE1) != HAL_OK)
    {
        Error_Handler();
    }

    RCC_ClkInitStruct.ClockType = RCC_CLOCKTYPE_SYSCLK;
    RCC_ClkInitStruct.SYSCLKSource = RCC_SYSCLKSOURCE_HSI;

    // Use HSI for SysClock while reconfiguring clocks.
    if (HAL_RCC_ClockConfig(&RCC_ClkInitStruct, FLASH_LATENCY_0) != HAL_OK)
    {
        _Error_Handler(__FILE_NAME__, __LINE__);
    }

    // Configure the Systick interrupt time
    HAL_SYSTICK_Config(HAL_RCC_GetHCLKFreq() / 1000);

    TPI->ACPR = 7; // 16MHz

    RCC_OscInitStruct.OscillatorType = RCC_OSCILLATORTYPE_HSE|RCC_OSCILLATORTYPE_MSI;
    RCC_OscInitStruct.HSEState = RCC_HSE_BYPASS;
    RCC_OscInitStruct.MSIState = RCC_MSI_OFF;
    RCC_OscInitStruct.PLL.PLLState = RCC_PLL_ON;
    RCC_OscInitStruct.PLL.PLLSource = RCC_PLLSOURCE_HSE;
    RCC_OscInitStruct.PLL.PLLM = 3;
    RCC_OscInitStruct.PLL.PLLN = 12;
    RCC_OscInitStruct.PLL.PLLP = RCC_PLLP_DIV2;
    RCC_OscInitStruct.PLL.PLLQ = RCC_PLLQ_DIV2;
    RCC_OscInitStruct.PLL.PLLR = RCC_PLLR_DIV2;

    HAL_StatusTypeDef result = HAL_RCC_OscConfig(&RCC_OscInitStruct);
    if (result != HAL_OK)
    {
        ERROR("HAL_RCC_OscConfig = %d", result);
        _Error_Handler2(__FILE_NAME__, __LINE__, result);
    }

    RCC_ClkInitStruct.ClockType = RCC_CLOCKTYPE_SYSCLK;
    RCC_ClkInitStruct.SYSCLKSource = RCC_SYSCLKSOURCE_PLLCLK;

    result = HAL_RCC_ClockConfig(&RCC_ClkInitStruct, FLASH_LATENCY_2);
    if (result != HAL_OK)
    {
        ERROR("HAL_RCC_ClockConfig = %d", result);
        _Error_Handler2(__FILE_NAME__, __LINE__, result);
    }

    TPI->ACPR = 23;
    __HAL_TIM_SET_PRESCALER(&LED_PWM_TIMER_HANDLE, 47);
    update_power_monitor_timer();

    // Configure the Systick interrupt time
    HAL_SYSTICK_Config(HAL_RCC_GetHCLKFreq() / 1000);

    xTaskResumeAll();

    INFO("CPU core clock: %luHz", SystemCoreClock);

#if defined(DEBUG)
    HAL_RCC_MCOConfig(RCC_MCO1, RCC_MCO1SOURCE_SYSCLK, RCC_MCODIV_8);
#else
    HAL_RCC_MCOConfig(RCC_MCO1, RCC_MCO1SOURCE_NOCLOCK, RCC_MCODIV_1);
#endif
}

void SysClock72()
{
    RCC_OscInitTypeDef RCC_OscInitStruct = { 0 };
    RCC_ClkInitTypeDef RCC_ClkInitStruct = { 0 };

    if (__HAL_RCC_GET_PLL_OSCSOURCE() == RCC_PLLSOURCE_HSE
            && HAL_RCC_GetHCLKFreq() == 72000000)
        return;

    INFO("Setting 72MHz SysClock.");

    // VDD must be enabled to use TCXO.
    if (!(VDD_EN_GPIO_Port->ODR & VDD_EN_Pin)) {
        _Error_Handler(__FILE_NAME__, __LINE__);
    }

    // Enable TCXO. The ECS-TXO-2520 has a start-up time of 10ms.
    HAL_GPIO_WritePin(TCXO_EN_GPIO_Port, TCXO_EN_Pin, GPIO_PIN_SET);

    DELAY(10);

    vTaskSuspendAll();

    // Set voltage regulator to normal run mode.
    HAL_PWREx_DisableLowPowerRunMode();
    HAL_RCCEx_DisableMSIPLLMode();
    if (HAL_PWREx_ControlVoltageScaling(PWR_REGULATOR_VOLTAGE_SCALE1)
            != HAL_OK) {
        Error_Handler();
    }

    RCC_ClkInitStruct.ClockType = RCC_CLOCKTYPE_SYSCLK;
    RCC_ClkInitStruct.SYSCLKSource = RCC_SYSCLKSOURCE_HSI;

    // Use HSI for SysClock while reconfiguring clocks.
    if (HAL_RCC_ClockConfig(&RCC_ClkInitStruct, FLASH_LATENCY_0) != HAL_OK) {
        _Error_Handler(__FILE_NAME__, __LINE__);
    }

    // Configure the Systick interrupt time
    HAL_SYSTICK_Config(HAL_RCC_GetHCLKFreq() / 1000);

    TPI->ACPR = 7; // 16MHz

    RCC_OscInitStruct.OscillatorType = RCC_OSCILLATORTYPE_HSE
            | RCC_OSCILLATORTYPE_MSI;
    RCC_OscInitStruct.HSEState = RCC_HSE_BYPASS;
    RCC_OscInitStruct.MSIState = RCC_MSI_OFF;
    RCC_OscInitStruct.PLL.PLLState = RCC_PLL_ON;
    RCC_OscInitStruct.PLL.PLLSource = RCC_PLLSOURCE_HSE;
    RCC_OscInitStruct.PLL.PLLM = 3;
    RCC_OscInitStruct.PLL.PLLN = 18;
    RCC_OscInitStruct.PLL.PLLP = RCC_PLLP_DIV2;
    RCC_OscInitStruct.PLL.PLLQ = RCC_PLLQ_DIV2;
    RCC_OscInitStruct.PLL.PLLR = RCC_PLLR_DIV2;

    HAL_StatusTypeDef result = HAL_RCC_OscConfig(&RCC_OscInitStruct);
    if (result != HAL_OK) {
        ERROR("HAL_RCC_OscConfig = %d", result);
        _Error_Handler(__FILE_NAME__, __LINE__);
    }

    RCC_ClkInitStruct.ClockType = RCC_CLOCKTYPE_SYSCLK;
    RCC_ClkInitStruct.SYSCLKSource = RCC_SYSCLKSOURCE_PLLCLK;

    result = HAL_RCC_ClockConfig(&RCC_ClkInitStruct, FLASH_LATENCY_3);
    if (result != HAL_OK) {
        ERROR("HAL_RCC_ClockConfig = %d", result);
        _Error_Handler(__FILE_NAME__, __LINE__);
    }

    TPI->ACPR = 35;
    __HAL_TIM_SET_PRESCALER(&LED_PWM_TIMER_HANDLE, 71);
    update_power_monitor_timer();

    // Configure the Systick interrupt time
    HAL_SYSTICK_Config(HAL_RCC_GetHCLKFreq() / 1000);

    xTaskResumeAll();

    INFO("CPU core clock: %luHz", SystemCoreClock);

#if defined(DEBUG)
    HAL_RCC_MCOConfig(RCC_MCO1, RCC_MCO1SOURCE_SYSCLK, RCC_MCODIV_8);
#else
    HAL_RCC_MCOConfig(RCC_MCO1, RCC_MCO1SOURCE_NOCLOCK, RCC_MCODIV_1);
#endif
}

/**
  * @brief  This function is executed in case of error occurrence.
  * @param  file: The file name as string.
  * @param  line: The line in file as a number.
  * @retval None
  */
void _Error_Handler(char *file, int line)
{
#ifdef KISS_LOGGING
  printf("Error handler called from file %s on line %d\r\n", file, line);
#endif
  snprintf(error_message, sizeof(error_message), "Error: %s:%d\r\n", file, line);
  error_message[sizeof(error_message) - 1] = 0;

  go_back_to_sleep = 0;

  vTaskSuspendAll(); // Will eventually cause IWDG reset.

  error_code(MORSE_1, MORSE_1);
}

void _Error_Handler2(char *file, int line, HAL_StatusTypeDef status)
{
#ifdef KISS_LOGGING
  printf("Error handler called from file %s on line %d\r\n", file, line);
#endif
  snprintf(error_message, sizeof(error_message), "Error: %s:%d, status = %d\r\n", file, line, status);
  error_message[sizeof(error_message) - 1] = 0;

  go_back_to_sleep = 0;

  vTaskSuspendAll(); // Will eventually cause IWDG reset.

  error_code(MORSE_1, MORSE_1);
}

void usbShutdownTimerCallback(void const * argument)
{
    UNUSED(argument);
    osMessagePut(ioEventQueueHandle, CMD_SHUTDOWN, 0);
}

void powerOffTimerCallback(void const * argument)
{
    UNUSED(argument);
    INFO("shutdown timer triggered");
    osMessagePut(ioEventQueueHandle, CMD_SHUTDOWN, 0);
}

void batteryCheckCallback(void const * argument)
{
    UNUSED(argument);
    HAL_IWDG_Refresh(&hiwdg); // Refresh IWDG in batteryCheckCallback.

    if (is_battery_low()) {
        HAL_NVIC_DisableIRQ(BT_STATE1_EXTI_IRQn);
        HAL_NVIC_DisableIRQ(BT_STATE2_EXTI_IRQn);

        vTaskSuspendAll();
        HAL_GPIO_WritePin(BT_SLEEP_GPIO_Port, BT_SLEEP_Pin, GPIO_PIN_RESET); // BT module on.
        _configure_power_on_disconnect();

        HAL_PWR_EnableBkUpAccess();
        WRITE_REG(BKUP_TNC_LOWPOWER_STATE, TNC_LOWPOWER_VBAT | TNC_LOWPOWER_LOW_BAT | TNC_LOWPOWER_STOP2 | TNC_LOWPOWER_RECONFIG);
        HAL_PWR_DisableBkUpAccess();
        HAL_NVIC_SystemReset();
    }
}

/* USER CODE END 4 */

__weak void startIOEventTask(void const * argument)
{
  for(;;)
  {
    osDelay(1);
  }
}

void HAL_TIM_PeriodElapsedCallback(TIM_HandleTypeDef *htim)
{
  if (htim->Instance == TIM15) {
    HAL_IncTick();
  }
  /* USER CODE BEGIN Callback 1 */
  if (htim->Instance == TIM8) {
      LED_TIMER_PeriodElapsedCallback();
  }
  /* USER CODE END Callback 1 */
}

void Error_Handler(void)
{
  /* USER CODE BEGIN Error_Handler_Debug */
  /* User can add his own implementation to report the HAL error return state */
  go_back_to_sleep = 0;
  NVIC_SystemReset();
  /* USER CODE END Error_Handler_Debug */
}

#ifdef  USE_FULL_ASSERT
/**
  * @brief  Reports the name of the source file and the source line number
  *         where the assert_param error has occurred.
  * @param  file: pointer to the source file name
  * @param  line: assert_param error line source number
  * @retval None
  */
void assert_failed(uint8_t *file, uint32_t line)
{
  /* USER CODE BEGIN 6 */
  /* User can add his own implementation to report the file name and line number,
     ex: printf("Wrong parameters value: file %s on line %d\r\n", file, line) */
  UNUSED(file);
  UNUSED(line);
  /* USER CODE END 6 */
}
#endif /* USE_FULL_ASSERT */

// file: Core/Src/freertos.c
/* USER CODE BEGIN Header */
/**
  ******************************************************************************
  * File Name          : freertos.c
  * Description        : Code for freertos applications
  ******************************************************************************
  * @attention
  *
  * <h2><center>&copy; Copyright (c) 2021 STMicroelectronics.
  * All rights reserved.</center></h2>
  *
  * This software component is licensed by ST under Ultimate Liberty license
  * SLA0044, the "License"; You may not use this file except in compliance with
  * the License. You may obtain a copy of the License at:
  *                             www.st.com/SLA0044
  *
  ******************************************************************************
  */
/* USER CODE END Header */

#include "FreeRTOS.h"
#include "task.h"
#include "main.h"

/* GetIdleTaskMemory prototype (linked to static allocation support) */
void vApplicationGetIdleTaskMemory( StaticTask_t **ppxIdleTaskTCBBuffer, StackType_t **ppxIdleTaskStackBuffer, uint32_t *pulIdleTaskStackSize );

/* GetTimerTaskMemory prototype (linked to static allocation support) */
void vApplicationGetTimerTaskMemory( StaticTask_t **ppxTimerTaskTCBBuffer, StackType_t **ppxTimerTaskStackBuffer, uint32_t *pulTimerTaskStackSize );

/* Hook prototypes */
void vApplicationStackOverflowHook(xTaskHandle xTask, signed char *pcTaskName);
void vApplicationMallocFailedHook(void);

/* USER CODE BEGIN 4 */
void vApplicationStackOverflowHook(xTaskHandle xTask, signed char *pcTaskName)
{
   /* Run time stack overflow checking is performed if
   configCHECK_FOR_STACK_OVERFLOW is defined to 1 or 2. This hook function is
   called if a stack overflow is detected. */
}
/* USER CODE END 4 */

/* USER CODE BEGIN 5 */
void vApplicationMallocFailedHook(void)
{
   /* vApplicationMallocFailedHook() will only be called if
   configUSE_MALLOC_FAILED_HOOK is set to 1 in FreeRTOSConfig.h. It is a hook
   function that will get called if a call to pvPortMalloc() fails.
   pvPortMalloc() is called internally by the kernel whenever a task, queue,
   timer or semaphore is created. It is also called by various parts of the
   demo application. If heap_1.c or heap_2.c are used, then the size of the
   heap available to pvPortMalloc() is defined by configTOTAL_HEAP_SIZE in
   FreeRTOSConfig.h, and the xPortGetFreeHeapSize() API function can be used
   to query the size of free heap space that remains (although it does not
   provide information on how the remaining heap might be fragmented). */
}
/* USER CODE END 5 */

/* USER CODE BEGIN VPORT_SUPPORT_TICKS_AND_SLEEP */
__weak void vPortSuppressTicksAndSleep( TickType_t xExpectedIdleTime )
{
  // Generated when configUSE_TICKLESS_IDLE == 2.
  // Function called in tasks.c (in portTASK_FUNCTION).
  // TO BE COMPLETED or TO BE REPLACED by a user one, overriding that weak one.
}
/* USER CODE END VPORT_SUPPORT_TICKS_AND_SLEEP */

/* USER CODE BEGIN GET_IDLE_TASK_MEMORY */
static StaticTask_t xIdleTaskTCBBuffer;
static StackType_t xIdleStack[configMINIMAL_STACK_SIZE];

void vApplicationGetIdleTaskMemory( StaticTask_t **ppxIdleTaskTCBBuffer, StackType_t **ppxIdleTaskStackBuffer, uint32_t *pulIdleTaskStackSize )
{
  *ppxIdleTaskTCBBuffer = &xIdleTaskTCBBuffer;
  *ppxIdleTaskStackBuffer = &xIdleStack[0];
  *pulIdleTaskStackSize = configMINIMAL_STACK_SIZE;
  /* place for user code */
}
/* USER CODE END GET_IDLE_TASK_MEMORY */

/* USER CODE BEGIN GET_TIMER_TASK_MEMORY */
static StaticTask_t xTimerTaskTCBBuffer;
static StackType_t xTimerStack[configTIMER_TASK_STACK_DEPTH];

void vApplicationGetTimerTaskMemory( StaticTask_t **ppxTimerTaskTCBBuffer, StackType_t **ppxTimerTaskStackBuffer, uint32_t *pulTimerTaskStackSize )
{
  *ppxTimerTaskTCBBuffer = &xTimerTaskTCBBuffer;
  *ppxTimerTaskStackBuffer = &xTimerStack[0];
  *pulTimerTaskStackSize = configTIMER_TASK_STACK_DEPTH;
  /* place for user code */
}
/* USER CODE END GET_TIMER_TASK_MEMORY */
